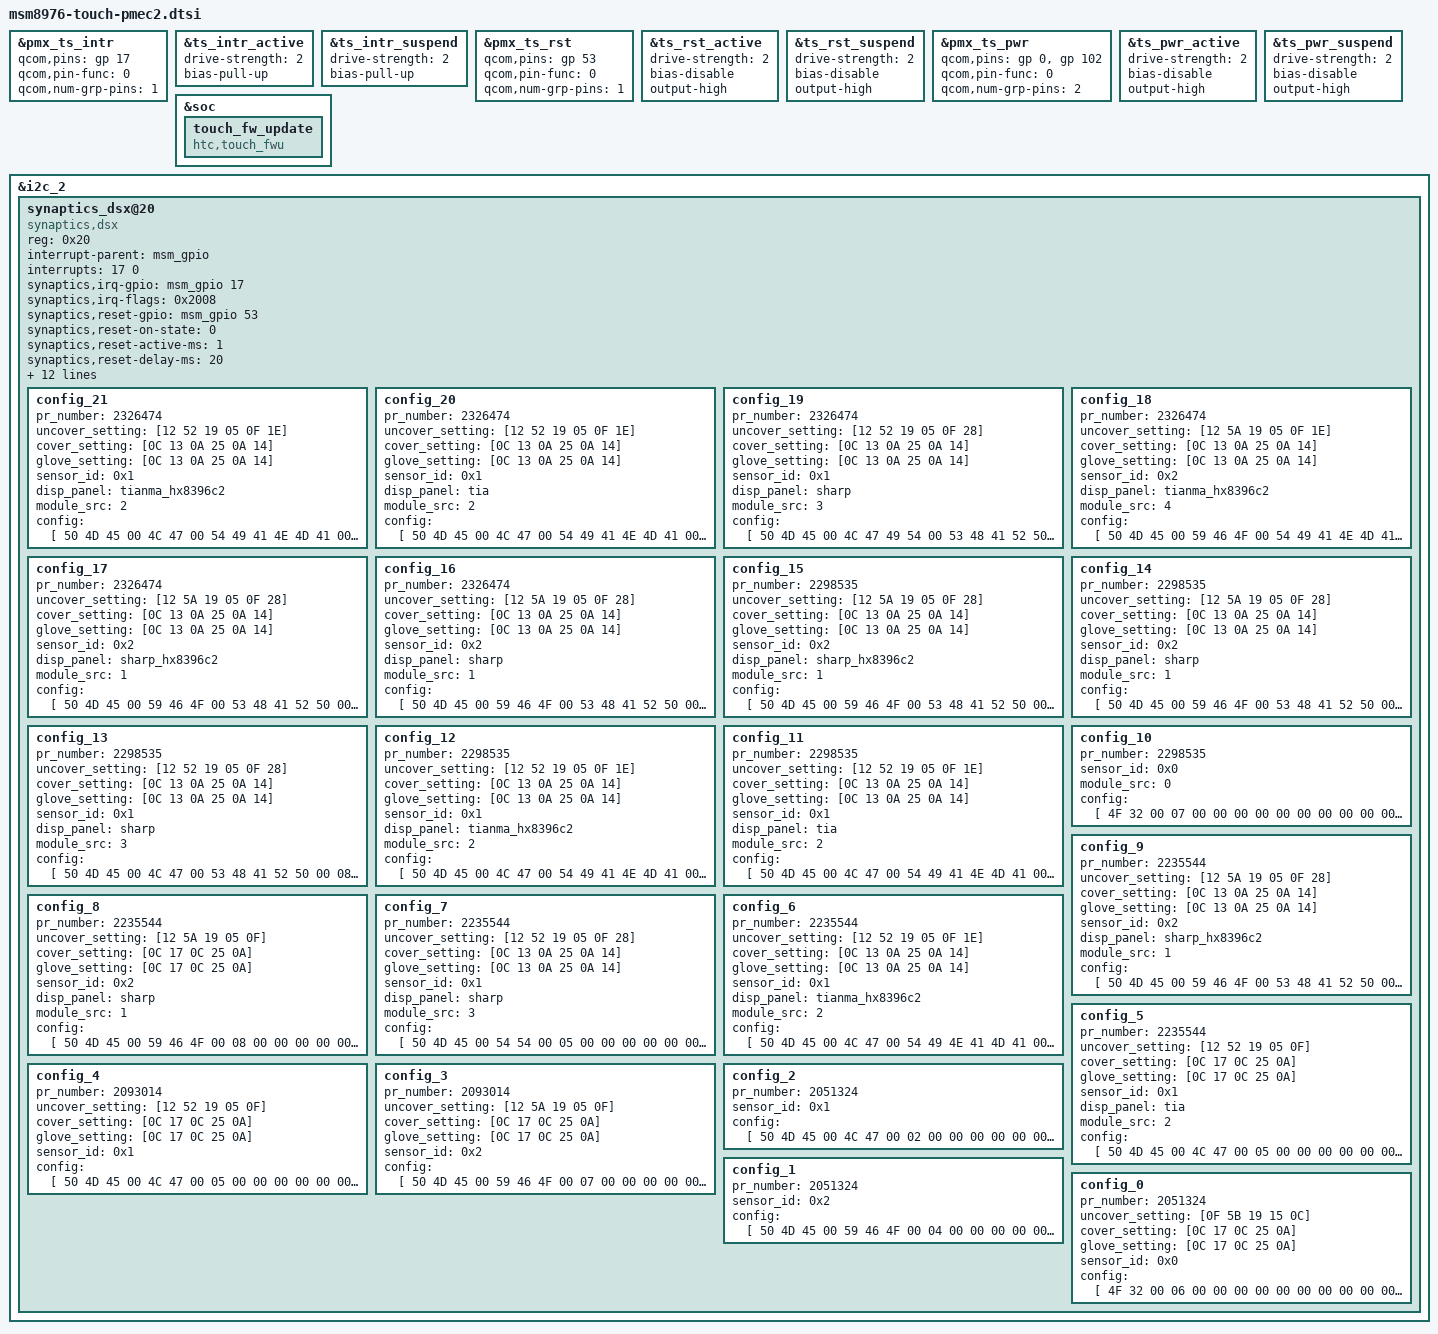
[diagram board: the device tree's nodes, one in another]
&pmx_ts_intr {
	qcom,pins = <&gp 17>;
	qcom,pin-func = <0>;
	qcom,num-grp-pins = <1>;
};

&ts_intr_active {
	drive-strength = <2>;
	bias-pull-up;
};

&ts_intr_suspend {
	drive-strength = <2>;
	bias-pull-up;
};

&pmx_ts_rst {
	qcom,pins = <&gp 53>;
	qcom,pin-func = <0>;
	qcom,num-grp-pins = <1>;
};

&ts_rst_active {
	drive-strength = <2>;
	bias-disable; /* No PULL */
	output-high;
};

&ts_rst_suspend {
	drive-strength = <2>;
	bias-disable; /* No PULL */
	output-high;
};

&pmx_ts_pwr {
	qcom,pins = <&gp 0>, <&gp 102>;
	qcom,pin-func = <0>;
	qcom,num-grp-pins = <2>;
};

&ts_pwr_active {
	drive-strength = <2>;
	bias-disable; /* No PULL */
	output-high;
};

&ts_pwr_suspend {
	drive-strength = <2>;
	bias-disable; /* No PULL */
	output-high;
};

&soc {
	touch_fw_update {
		compatible = "htc,touch_fwu";
	};
};

&i2c_2 {
	synaptics_dsx@20 {
		compatible = "synaptics,dsx";
		reg = <0x20>;
		interrupt-parent = <&msm_gpio>;
		interrupts = <17 0>;
		synaptics,irq-gpio = <&msm_gpio 17 0x00>;
		synaptics,irq-flags = <0x2008>;
		synaptics,reset-gpio = <&msm_gpio 53 0x00>;
		synaptics,reset-on-state = <0>;
		synaptics,reset-active-ms = <1>;
		synaptics,reset-delay-ms = <20>;
		synaptics,switch-gpio = <&msm_gpio 49 0x00>;
		synaptics,update-feature = <2>;
		synaptics,support-glove = <1>;
		synaptics,support-cover = <1>;
		synaptics,hall-block-time = <1000>;
		synaptics,setting-group=<1>;
		synaptics,display-coords = <0 1440 0 2560>;
		synaptics,tw-pin-mask = <0x3>;
		pinctrl-names = "pmx_ts_active", "pmx_ts_suspend";
		pinctrl-0 = <&ts_intr_active &ts_rst_active &ts_pwr_active>;
		pinctrl-1 = <&ts_intr_suspend &ts_rst_suspend &ts_pwr_suspend>;

		config_21 { /* LGIT + Tianma cut 2.0 */
			pr_number     = <2326474>;
			uncover_setting = [12 52 19 05 0F 1E];
			cover_setting = [0C 13 0A 25 0A 14];
			glove_setting = [0C 13 0A 25 0A 14];
			sensor_id = <0x1>;
			disp_panel = "tianma_hx8396c2";
			module_src = <2>;
			config = [
				50 4D 45 00 4C 47 00 54
				49 41 4E 4D 41 00 11 00
				00 00 00 00 00 00 00 00
				00 00 00 00 00 00 00 00
				00 4F 01 1E 05 51 0E 9F
				05 FF 09 7D 3D 79 3D 00
				00 00 00 11 1E 1E 05 C2
				04 F8 00 2D 19 01 15 02
				F0 D2 F0 D2 6D 0D 05 46
				00 00 0F 12 4B 0F 0A 78
				00 01 01 07 04 04 32 28
				08 C8 26 26 80 80 00 00
				FF 01 64 00 05 0F 00 FF
				05 01 28 FF C0 53 5B 80
				52 19 00 40 40 32 50 00
				00 00 00 4C 04 6C 07 3C
				32 00 00 00 00 4C 04 6C
				07 1E 05 1E 04 0A 04 0A
				00 0A 04 04 00 0A 78 02
				00 7D 00 02 00 C8 00 00
				00 96 00 00 00 00 01 05
				0A 00 00 00 78 00 96 00
				32 00 00 00 00 00 00 00
				00 00 0D 00 00 14 03 0C
				0F 0A 00 4B 00 00 FF FF
				FF FF FF FF FF FF FF FF
				FF FF FF FF FF FF FF FF
				FF FF FF FF FF FF FF FF
				FF FF FF FF FF FF FF 00
				01 00 00 32 00 14 00 14
				00 64 00 64 00 10 00 10
				00 7D 00 7D 00 40 66 58
				1B 28 00 FF FF FF FF FF
				FF FF FF FF FF FF FF FF
				FF FF FF 01 00 00 00 00
				00 00 00 00 00 00 00 00
				00 00 00 00 00 00 00 00
				00 00 FF 00 FF 14 55 09
				0E 3C 0A 0F 64 64 00 00
				00 00 00 00 00 00 00 00
				00 00 00 00 00 00 00 00
				FF FF FF FF FF FF FF FF
				FF FF FF FF FF FF FF FF
				FF FF FF FF FF FF FF FF
				FF FF FF FF FF FF FF FF
				FF FF FF FF FF FF FF FF
				FF FF FF FF FF FF FF FF
				FF FF FF FF FF FF FF FF
				FF FF FF FF FF FF FF FF
				00 00 6E 00 80 04 1B 00
				00 FF 2C 01 FF FF CC 03
				E8 03 00 C0 80 04 10 0A
				18 00 79 08 08 00 01 2C
				01 06 00 06 06 07 07 00
				2C 01 01 04 03 36 00 19
				00 00 00 02 00 01 28 04
				35 00 19 00 01 00 02 00
				01 29 84 34 00 18 00 02
				00 02 00 01 2A 83 33 00
				17 00 03 00 02 00 01 2B
				83 32 00 17 00 04 00 02
				00 01 2C 83 31 00 17 00
				05 00 02 00 01 2D 03 30
				00 16 00 06 00 05 00 02
				26 03 2F 00 16 00 07 00
				05 00 02 27 05 05 05 05
				05 05 05 05 05 05 05 05
				05 05 05 05 05 00 00 00
				00 00 00 00 00 00 00 00
				00 00 00 00 00 00 1B 00
				06 00 0A 00 0A 32 00 01
				1B 01 06 46 46 50 00 50
				00 00 8C 1E 03 0C 0C 14
				28 04 00 00 00 00 00 00
				00 00 00 00 18 00 80 07
				01 07 07 1D 1D 00 00 07
				07 01 07 07 1D 1D 00 00
				07 04 04 39 00 07 03 00
				36 22 00 05 03 00 25 01
				00 00 04 0C EE EE 00 0C
				EE EE AA 01 28 0C 11 11
				00 0C 66 66 AA 00 00 00
				FF FF FF FF FF FF FF FF
				51 51 51 51 CD 0D 04 83
				10 10 10 10 61 24 64 01
				1C 19 1E 1F 17 16 1A 18
				15 14 13 11 12 04 05 03
				06 FF FF FF FF FF FF FF
				FF FF FF FF FF FF FF FF
				FF FF 30 2E 2F 28 27 2D
				29 2A 2C 2B 26 23 24 25
				22 39 35 36 3A 3B 3E 3F
				31 3C 38 3D 37 00 32 01
				FF FF FF FF 00 10 00 10
				00 10 00 10 80 80 80 80
				80 80 80 80 80 80 80 80
				80 80 80 80 80 80 80 80
				80 80 80 80 80 80 80 80
				80 80 80 80 80 80 A6 9A
				8D 86 80 80 80 80 80 80
				80 80 80 80 80 80 80 80
				80 80 80 80 80 80 80 80
				80 80 80 80 80 80 80 80
				CD 14 CD 14 00 10 00 10
				00 00 1D FF FF FF FF FF
				FF FF 00 00 0F 00 44 44
				78
			];
		};

		config_20 { /* LGIT + Tianma */
			pr_number     = <2326474>;
			uncover_setting = [12 52 19 05 0F 1E];
			cover_setting = [0C 13 0A 25 0A 14];
			glove_setting = [0C 13 0A 25 0A 14];
			sensor_id = <0x1>;
			disp_panel = "tia";
			module_src = <2>;
			config = [
				50 4D 45 00 4C 47 00 54
				49 41 4E 4D 41 00 10 10
				00 00 00 00 00 00 00 00
				00 00 00 00 00 00 00 00
				00 4F 01 1E 05 51 0E 9F
				05 FF 09 7D 3D 79 3D 00
				00 00 00 11 1E 1E 05 C2
				04 F8 00 2D 19 01 15 02
				F0 D2 F0 D2 6D 0D 05 46
				00 00 0F 12 5F 0F 0A 78
				00 01 01 07 04 04 32 28
				08 C8 26 26 80 80 00 00
				FF 01 64 00 05 0F 00 FF
				05 01 28 FF C0 53 5B 80
				52 19 00 40 40 32 50 00
				00 00 00 4C 04 6C 07 3C
				32 00 00 00 00 4C 04 6C
				07 1E 05 1E 04 0A 04 0A
				00 0A 04 04 00 0A 78 02
				00 7D 00 02 00 C8 00 00
				00 96 00 00 00 00 01 05
				0A 00 00 00 78 00 96 00
				32 00 00 00 00 00 00 00
				00 00 0D 00 00 14 03 0C
				0F 0A 00 4B 00 00 FF FF
				FF FF FF FF FF FF FF FF
				FF FF FF FF FF FF FF FF
				FF FF FF FF FF FF FF FF
				FF FF FF FF FF FF FF 00
				01 00 00 32 00 14 00 14
				00 64 00 64 00 10 00 10
				00 7D 00 7D 00 40 66 58
				1B 28 00 FF FF FF FF FF
				FF FF FF FF FF FF FF FF
				FF FF FF 01 00 00 00 00
				00 00 00 00 00 00 00 00
				00 00 00 00 00 00 00 00
				00 00 FF 00 FF 14 55 09
				0E 3C 0A 0F 64 64 00 00
				00 00 00 00 00 00 00 00
				00 00 00 00 00 00 00 00
				FF FF FF FF FF FF FF FF
				FF FF FF FF FF FF FF FF
				FF FF FF FF FF FF FF FF
				FF FF FF FF FF FF FF FF
				FF FF FF FF FF FF FF FF
				FF FF FF FF FF FF FF FF
				FF FF FF FF FF FF FF FF
				FF FF FF FF FF FF FF FF
				00 00 6E 00 80 04 1B 00
				00 FF 2C 01 FF FF CC 03
				E8 03 00 C0 80 04 10 0A
				18 00 79 08 08 00 01 2C
				01 06 00 06 06 07 07 00
				2C 01 01 04 03 36 00 19
				00 00 00 02 00 01 28 04
				35 00 19 00 01 00 02 00
				01 29 84 34 00 18 00 02
				00 02 00 01 2A 83 33 00
				17 00 03 00 02 00 01 2B
				83 32 00 17 00 04 00 02
				00 01 2C 83 31 00 17 00
				05 00 02 00 01 2D 03 30
				00 16 00 06 00 05 00 02
				26 03 2F 00 16 00 07 00
				05 00 02 27 05 05 05 05
				05 05 05 05 05 05 05 05
				05 05 05 05 05 00 00 00
				00 00 00 00 00 00 00 00
				00 00 00 00 00 00 1B 00
				06 00 0A 00 0A 32 00 01
				1B 01 06 46 46 50 00 50
				00 00 8C 1E 03 0C 0C 14
				28 04 00 00 00 00 00 00
				00 00 00 00 18 00 80 07
				01 07 07 1D 1D 00 00 07
				07 01 07 07 1D 1D 00 00
				07 04 04 39 00 07 03 00
				36 22 00 05 03 00 25 01
				00 00 04 0C EE EE 00 0C
				EE EE AA 01 28 0C 11 11
				00 0C 66 66 AA 00 00 00
				FF FF FF FF FF FF FF FF
				51 51 51 51 CD 0D 04 83
				10 10 10 10 61 24 64 01
				1C 19 1E 1F 17 16 1A 18
				15 14 13 11 12 04 05 03
				06 FF FF FF FF FF FF FF
				FF FF FF FF FF FF FF FF
				FF FF 30 2E 2F 28 27 2D
				29 2A 2C 2B 26 23 24 25
				22 39 35 36 3A 3B 3E 3F
				31 3C 38 3D 37 00 32 01
				FF FF FF FF 00 10 00 10
				00 10 00 10 80 80 80 80
				80 80 80 80 80 80 80 80
				80 80 80 80 80 80 80 80
				80 80 80 80 80 80 80 80
				80 80 80 80 80 80 A6 9A
				8D 86 80 80 80 80 80 80
				80 80 80 80 80 80 80 80
				80 80 80 80 80 80 80 80
				80 80 80 80 80 80 80 80
				CD 14 CD 14 00 10 00 10
				00 00 1D FF FF FF FF FF
				FF FF 00 00 0F 00 44 44
				78
			];
		};

		config_19 { /* LGIT + Sharp (cut 2.0 only) */
			pr_number     = <2326474>;
			uncover_setting = [12 52 19 05 0F 28];
			cover_setting = [0C 13 0A 25 0A 14];
			glove_setting = [0C 13 0A 25 0A 14];
			sensor_id = <0x1>;
			disp_panel = "sharp";
			module_src = <3>;
			config = [
				50 4D 45 00 4C 47 49 54
				00 53 48 41 52 50 10 00
				00 00 00 00 00 00 00 00
				00 00 00 00 00 00 00 00
				00 4F 01 28 05 51 0E 9F
				05 FF 09 7D 3D 79 3D 00
				00 00 00 11 1E 1E 05 C2
				04 F8 00 2D 19 01 15 02
				F0 D2 F0 D2 6D 0D 05 46
				00 00 0F 12 5F 0F 0A 78
				00 01 01 07 04 04 32 28
				08 7D 26 26 80 80 00 00
				FF 01 64 00 05 0F 00 FF
				05 01 28 FF C0 53 5B 80
				52 19 00 40 40 32 50 00
				00 00 00 4C 04 6C 07 3C
				32 00 00 00 00 4C 04 6C
				07 1E 05 1E 04 0A 04 0A
				00 0A 04 04 00 0A 78 02
				00 7D 00 02 00 C8 00 00
				00 96 00 00 00 00 01 05
				0A 00 00 00 78 00 96 00
				32 00 00 00 00 00 00 00
				00 00 0D 00 00 14 03 0C
				0F 0A 00 4B 00 00 FF FF
				FF FF FF FF FF FF FF FF
				FF FF FF FF FF FF FF FF
				FF FF FF FF FF FF FF FF
				FF FF FF FF FF FF FF 00
				01 00 00 32 00 14 00 14
				00 64 00 64 00 10 00 10
				00 7D 00 7D 00 40 66 58
				1B 28 00 FF FF FF FF FF
				FF FF FF FF FF FF FF FF
				FF FF FF 01 00 00 00 00
				00 00 00 00 00 00 00 00
				00 00 00 00 00 00 00 00
				00 00 FF 00 FF 14 55 09
				0E 3C 0A 0F 64 64 00 00
				00 00 00 00 00 00 00 00
				00 00 00 00 00 00 00 00
				FF FF FF FF FF FF FF FF
				FF FF FF FF FF FF FF FF
				FF FF FF FF FF FF FF FF
				FF FF FF FF FF FF FF FF
				FF FF FF FF FF FF FF FF
				FF FF FF FF FF FF FF FF
				FF FF FF FF FF FF FF FF
				FF FF FF FF FF FF FF FF
				00 00 6E 00 80 04 1B 00
				00 FF 20 03 FF FF CC 03
				DC 05 00 C0 80 04 10 0A
				18 00 79 08 06 00 01 20
				03 06 00 06 06 07 07 00
				2C 01 01 04 03 36 00 19
				00 00 00 02 00 01 28 04
				35 00 19 00 01 00 02 00
				01 29 84 34 00 18 00 02
				00 02 00 01 2A 83 33 00
				17 00 03 00 02 00 01 2B
				83 32 00 17 00 04 00 02
				00 01 2C 83 31 00 17 00
				05 00 02 00 01 2D 03 30
				00 16 00 06 00 05 00 02
				26 03 2F 00 16 00 07 00
				05 00 02 27 05 05 05 05
				05 05 05 05 05 05 05 05
				05 05 05 05 05 00 00 00
				00 00 00 00 00 00 00 00
				00 00 00 00 00 00 1B 00
				06 00 0A 00 0A 32 00 01
				1B 01 06 46 46 50 00 50
				00 00 8C 1E 03 0C 0C 14
				28 04 00 00 00 00 00 00
				00 00 00 00 18 00 80 07
				01 07 07 1D 1D 00 00 07
				07 01 07 07 1D 1D 00 00
				07 04 04 2D 00 07 03 00
				36 22 00 05 03 00 25 01
				00 00 04 0C EE EE 00 0C
				EE EE AA 01 3C 0C 11 11
				00 0C 66 66 AA 00 00 00
				FF FF FF FF FF FF FF FF
				51 51 51 51 CD 0D 04 83
				10 10 10 10 61 24 64 01
				1C 19 1E 1F 17 16 1A 18
				15 14 13 11 12 04 05 03
				06 FF FF FF FF FF FF FF
				FF FF FF FF FF FF FF FF
				FF FF 30 2E 2F 28 27 2D
				29 2A 2C 2B 26 23 24 25
				22 39 35 36 3A 3B 3E 3F
				31 3C 38 3D 37 00 32 01
				FF FF FF FF 00 10 00 10
				00 10 00 10 80 80 80 80
				80 80 80 80 80 80 80 80
				80 80 80 80 80 80 80 80
				80 80 80 80 80 80 80 80
				80 80 80 80 80 80 A6 9A
				8D 86 80 80 80 80 80 80
				80 80 80 80 80 80 80 80
				80 80 80 80 80 80 80 80
				80 80 80 80 80 80 80 80
				CD 14 CD 14 00 10 00 10
				00 00 1D FF FF FF FF FF
				FF FF 00 00 0F 00 44 44
				78
			];
		};

		config_18 { /* YFO_R2 + Tianma (cut 2.0 only) */
			pr_number     = <2326474>;
			uncover_setting = [12 5A 19 05 0F 1E];
			cover_setting = [0C 13 0A 25 0A 14];
			glove_setting = [0C 13 0A 25 0A 14];
			sensor_id = <0x2>;
			disp_panel = "tianma_hx8396c2";
			module_src = <4>;
			config = [
				50 4D 45 00 59 46 4F 00
				54 49 41 4E 4D 41 00 02
				00 00 00 00 00 00 00 00
				00 00 00 00 00 00 00 00
				00 4F 01 1E 05 51 0E 9F
				05 FF 09 7D 3D 79 3D 00
				00 00 00 11 1E 1E 05 C2
				04 F8 00 2D 19 01 15 02
				F0 D2 F0 D2 6D 0D 05 46
				00 00 0F 12 4B 0F 0A 78
				00 01 01 07 04 04 32 28
				08 C8 26 26 80 80 00 00
				FF 01 64 00 05 0F 00 FF
				05 01 28 FF C0 53 5B 80
				5A 19 00 40 40 32 50 00
				00 00 00 4C 04 6C 07 3C
				32 00 00 00 00 4C 04 6C
				07 1E 05 1E 04 0A 04 0A
				00 0A 04 04 00 0A 78 02
				00 7D 00 02 00 C8 00 00
				00 96 00 00 00 00 01 05
				0A 00 00 00 78 00 96 00
				32 00 00 00 00 00 00 00
				00 00 0D 00 00 14 03 0C
				0F 0A 00 4B 00 00 FF FF
				FF FF FF FF FF FF FF FF
				FF FF FF FF FF FF FF FF
				FF FF FF FF FF FF FF FF
				FF FF FF FF FF FF FF 00
				01 00 00 32 00 14 00 14
				00 64 00 64 00 10 00 10
				00 7D 00 7D 00 40 66 58
				1B 28 00 FF FF FF FF FF
				FF FF FF FF FF FF FF FF
				FF FF FF 01 00 00 00 00
				00 00 00 00 00 00 00 00
				00 00 00 00 00 00 00 00
				00 00 FF 00 FF 14 55 09
				0E 3C 0A 0F 64 64 00 00
				00 00 00 00 00 00 00 00
				00 00 00 00 00 00 00 00
				FF FF FF FF FF FF FF FF
				FF FF FF FF FF FF FF FF
				FF FF FF FF FF FF FF FF
				FF FF FF FF FF FF FF FF
				FF FF FF FF FF FF FF FF
				FF FF FF FF FF FF FF FF
				FF FF FF FF FF FF FF FF
				FF FF FF FF FF FF FF FF
				00 00 6E 00 80 04 1B 00
				00 FF 2C 01 FF FF CC 03
				E8 03 00 C0 80 04 10 0A
				18 00 79 08 08 00 01 2C
				01 06 00 06 06 07 07 00
				2C 01 01 04 03 36 00 19
				00 00 00 02 00 01 28 04
				35 00 19 00 01 00 02 00
				01 29 84 34 00 18 00 02
				00 02 00 01 2A 83 33 00
				17 00 03 00 02 00 01 2B
				83 32 00 17 00 04 00 02
				00 01 2C 83 31 00 17 00
				05 00 02 00 01 2D 03 30
				00 16 00 06 00 05 00 02
				26 03 2F 00 16 00 07 00
				05 00 02 27 05 05 05 05
				05 05 05 05 05 05 05 05
				05 05 05 05 05 00 00 00
				00 00 00 00 00 00 00 00
				00 00 00 00 00 00 1B 00
				06 00 0A 00 0A 32 00 01
				1B 01 06 46 46 50 00 50
				00 00 8C 1E 03 0C 0C 14
				28 04 00 00 00 00 00 00
				00 00 00 00 18 00 80 07
				01 07 07 1D 1D 00 00 07
				07 01 07 07 1D 1D 00 00
				07 04 04 39 00 07 03 00
				36 22 00 05 03 00 25 01
				00 00 04 0C EE EE 00 0C
				EE EE AA 01 28 0C 11 11
				00 0C 66 66 AA 00 00 00
				FF FF FF FF FF FF FF FF
				51 51 51 51 CD 0D 04 83
				10 10 10 10 61 24 64 01
				1C 19 1E 1F 17 16 1A 18
				15 14 13 11 12 04 05 03
				06 FF FF FF FF FF FF FF
				FF FF FF FF FF FF FF FF
				FF FF 30 2E 2F 28 27 2D
				29 2A 2C 2B 26 23 24 25
				22 39 35 3C 3A 3B 3E 3F
				31 36 38 3D 37 00 32 01
				FF FF FF FF 00 10 00 10
				00 10 00 10 80 80 80 80
				80 80 80 80 80 80 80 80
				80 80 80 80 80 80 80 80
				80 80 80 80 80 80 80 80
				80 80 80 80 80 80 A6 9A
				8D 86 80 80 80 80 80 80
				80 80 80 80 80 80 80 80
				80 80 80 80 80 80 80 80
				80 80 80 80 80 80 80 80
				CD 14 CD 14 00 10 00 10
				00 00 1D FF FF FF FF FF
				FF FF 00 00 0F 00 44 44
				78
			];
		};

		config_17 { /* YFO R2 + Sharp cut 2.0 */
			pr_number     = <2326474>;
			uncover_setting = [12 5A 19 05 0F 28];
			cover_setting = [0C 13 0A 25 0A 14];
			glove_setting = [0C 13 0A 25 0A 14];
			sensor_id = <0x2>;
			disp_panel = "sharp_hx8396c2";
			module_src = <1>;
			config = [
				50 4D 45 00 59 46 4F 00
				53 48 41 52 50 00 11 00
				00 00 00 00 00 00 00 00
				00 00 00 00 00 00 00 00
				00 4F 01 28 05 51 0E 9F
				05 FF 09 7D 3D 79 3D 00
				00 00 00 11 1E 1E 05 6B
				08 60 01 2D 17 02 14 02
				F0 D2 F0 D2 6D 0D 05 46
				00 00 0F 12 4B 0F 0A 78
				00 01 01 07 04 04 32 28
				08 7D 26 26 80 80 00 00
				FF 01 64 00 05 0F 00 FF
				05 01 28 FF C0 53 5B 80
				5A 19 00 40 40 32 50 00
				00 00 00 4C 04 6C 07 3C
				32 00 00 00 00 4C 04 6C
				07 1E 05 1E 04 0A 04 0A
				00 0A 04 04 00 0A 78 02
				00 7D 00 02 00 C8 00 00
				00 96 00 00 00 00 01 05
				0A 00 00 00 78 00 96 00
				32 00 00 00 00 00 00 00
				00 00 0D 00 00 14 03 0C
				0F 0A 00 4B 00 00 FF FF
				FF FF FF FF FF FF FF FF
				FF FF FF FF FF FF FF FF
				FF FF FF FF FF FF FF FF
				FF FF FF FF FF FF FF 00
				01 00 00 32 00 14 00 14
				00 64 00 64 00 10 00 10
				00 7D 00 7D 00 40 66 58
				1B 28 00 FF FF FF FF FF
				FF FF FF FF FF FF FF FF
				FF FF FF 01 00 00 00 00
				00 00 00 00 00 00 00 00
				00 00 00 00 00 00 00 00
				00 00 FF 00 FF 14 55 09
				0E 3C 0A 0F 64 64 00 00
				00 00 00 00 00 00 00 00
				00 00 00 00 00 00 00 00
				FF FF FF FF FF FF FF FF
				FF FF FF FF FF FF FF FF
				FF FF FF FF FF FF FF FF
				FF FF FF FF FF FF FF FF
				FF FF FF FF FF FF FF FF
				FF FF FF FF FF FF FF FF
				FF FF FF FF FF FF FF FF
				FF FF FF FF FF FF FF FF
				00 00 6E 00 80 04 1B 00
				00 FF 20 03 FF FF CC 03
				DC 05 00 C0 80 04 10 0A
				18 00 79 08 06 00 01 20
				03 06 00 03 03 07 07 03
				2C 01 01 04 03 36 00 19
				00 00 00 02 00 01 28 04
				35 00 19 00 01 00 02 00
				01 29 84 34 00 18 00 02
				00 02 00 01 2A 83 33 00
				17 00 03 00 02 00 01 2B
				83 32 00 17 00 04 00 02
				00 01 2C 83 31 00 17 00
				05 00 02 00 01 2D 03 30
				00 16 00 06 00 05 00 02
				26 03 2F 00 16 00 07 00
				05 00 02 27 06 06 06 06
				06 06 06 06 06 06 06 05
				05 05 05 06 05 00 00 00
				00 00 00 00 00 00 00 00
				00 00 00 00 00 00 1B 00
				06 00 0A 00 0A 32 00 01
				1B 01 06 46 46 50 00 50
				00 00 8C 1E 03 0C 0C 14
				28 04 00 00 00 00 00 00
				00 00 00 00 18 00 80 07
				01 07 07 1D 1D 00 00 07
				07 01 07 07 1D 1D 00 00
				07 04 04 2D 00 07 03 00
				36 22 00 05 03 00 25 01
				00 00 04 0C EE EE 00 0C
				EE EE AA 01 3C 0C 11 11
				00 0C 66 66 AA 00 00 00
				FF FF FF FF FF FF FF FF
				51 51 51 51 CD 0D 04 83
				10 10 10 10 61 24 64 01
				1C 19 1E 1F 17 16 1A 18
				15 14 13 11 12 04 05 03
				06 FF FF FF FF FF FF FF
				FF FF FF FF FF FF FF FF
				FF FF 30 2E 2F 28 27 2D
				29 2A 2C 2B 26 23 24 25
				22 39 35 3C 3A 3B 3E 3F
				31 36 38 3D 37 00 32 01
				FF FF FF FF 00 10 00 10
				00 10 00 10 80 80 80 80
				80 80 80 80 80 80 80 80
				80 80 80 80 80 80 80 80
				80 80 80 80 80 80 80 80
				80 80 80 80 80 80 A6 9A
				8D 86 80 80 80 80 80 80
				80 80 80 80 80 80 80 80
				80 80 80 80 80 80 80 80
				80 80 80 80 80 80 80 80
				CD 14 CD 14 00 10 00 10
				00 00 1D FF FF FF FF FF
				FF FF 00 00 0F 00 44 44
				78
			];
		};

		config_16 { /* YFO R2 + Sharp */
			pr_number     = <2326474>;
			uncover_setting = [12 5A 19 05 0F 28];
			cover_setting = [0C 13 0A 25 0A 14];
			glove_setting = [0C 13 0A 25 0A 14];
			sensor_id = <0x2>;
			disp_panel = "sharp";
			module_src = <1>;
			config = [
				50 4D 45 00 59 46 4F 00
				53 48 41 52 50 00 10 10
				00 00 00 00 00 00 00 00
				00 00 00 00 00 00 00 00
				00 4F 01 28 05 51 0E 9F
				05 FF 09 7D 3D 79 3D 00
				00 00 00 11 1E 1E 05 6B
				08 60 01 2D 17 02 14 02
				F0 D2 F0 D2 6D 0D 05 46
				00 00 0F 12 5F 0F 0A 78
				00 01 01 07 04 04 32 28
				08 7D 26 26 80 80 00 00
				FF 01 64 00 05 0F 00 FF
				05 01 28 FF C0 53 5B 80
				5A 19 00 40 40 32 50 00
				00 00 00 4C 04 6C 07 3C
				32 00 00 00 00 4C 04 6C
				07 1E 05 1E 04 0A 04 0A
				00 0A 04 04 00 0A 78 02
				00 7D 00 02 00 C8 00 00
				00 96 00 00 00 00 01 05
				0A 00 00 00 78 00 96 00
				32 00 00 00 00 00 00 00
				00 00 0D 00 00 14 03 0C
				0F 0A 00 4B 00 00 FF FF
				FF FF FF FF FF FF FF FF
				FF FF FF FF FF FF FF FF
				FF FF FF FF FF FF FF FF
				FF FF FF FF FF FF FF 00
				01 00 00 32 00 14 00 14
				00 64 00 64 00 10 00 10
				00 7D 00 7D 00 40 66 58
				1B 28 00 FF FF FF FF FF
				FF FF FF FF FF FF FF FF
				FF FF FF 01 00 00 00 00
				00 00 00 00 00 00 00 00
				00 00 00 00 00 00 00 00
				00 00 FF 00 FF 14 55 09
				0E 3C 0A 0F 64 64 00 00
				00 00 00 00 00 00 00 00
				00 00 00 00 00 00 00 00
				FF FF FF FF FF FF FF FF
				FF FF FF FF FF FF FF FF
				FF FF FF FF FF FF FF FF
				FF FF FF FF FF FF FF FF
				FF FF FF FF FF FF FF FF
				FF FF FF FF FF FF FF FF
				FF FF FF FF FF FF FF FF
				FF FF FF FF FF FF FF FF
				00 00 6E 00 80 04 1B 00
				00 FF 20 03 FF FF CC 03
				DC 05 00 C0 80 04 10 0A
				18 00 79 08 06 00 01 20
				03 06 00 03 03 07 07 03
				2C 01 01 04 03 36 00 19
				00 00 00 02 00 01 28 04
				35 00 19 00 01 00 02 00
				01 29 84 34 00 18 00 02
				00 02 00 01 2A 83 33 00
				17 00 03 00 02 00 01 2B
				83 32 00 17 00 04 00 02
				00 01 2C 83 31 00 17 00
				05 00 02 00 01 2D 03 30
				00 16 00 06 00 05 00 02
				26 03 2F 00 16 00 07 00
				05 00 02 27 06 06 06 06
				06 06 06 06 06 06 06 05
				05 05 05 06 05 00 00 00
				00 00 00 00 00 00 00 00
				00 00 00 00 00 00 1B 00
				06 00 0A 00 0A 32 00 01
				1B 01 06 46 46 50 00 50
				00 00 8C 1E 03 0C 0C 14
				28 04 00 00 00 00 00 00
				00 00 00 00 18 00 80 07
				01 07 07 1D 1D 00 00 07
				07 01 07 07 1D 1D 00 00
				07 04 04 2D 00 07 03 00
				36 22 00 05 03 00 25 01
				00 00 04 0C EE EE 00 0C
				EE EE AA 01 3C 0C 11 11
				00 0C 66 66 AA 00 00 00
				FF FF FF FF FF FF FF FF
				51 51 51 51 CD 0D 04 83
				10 10 10 10 61 24 64 01
				1C 19 1E 1F 17 16 1A 18
				15 14 13 11 12 04 05 03
				06 FF FF FF FF FF FF FF
				FF FF FF FF FF FF FF FF
				FF FF 30 2E 2F 28 27 2D
				29 2A 2C 2B 26 23 24 25
				22 39 35 3C 3A 3B 3E 3F
				31 36 38 3D 37 00 32 01
				FF FF FF FF 00 10 00 10
				00 10 00 10 80 80 80 80
				80 80 80 80 80 80 80 80
				80 80 80 80 80 80 80 80
				80 80 80 80 80 80 80 80
				80 80 80 80 80 80 A6 9A
				8D 86 80 80 80 80 80 80
				80 80 80 80 80 80 80 80
				80 80 80 80 80 80 80 80
				80 80 80 80 80 80 80 80
				CD 14 CD 14 00 10 00 10
				00 00 1D FF FF FF FF FF
				FF FF 00 00 0F 00 44 44
				78
			];
		};

		config_15 { /* YFO R2 + Sharp cut 2.0 */
			pr_number     = <2298535>;
			uncover_setting = [12 5A 19 05 0F 28];
			cover_setting = [0C 13 0A 25 0A 14];
			glove_setting = [0C 13 0A 25 0A 14];
			sensor_id = <0x2>;
			disp_panel = "sharp_hx8396c2";
			module_src = <1>;
			config = [
				50 4D 45 00 59 46 4F 00
				53 48 41 52 50 00 08 00
				00 00 00 00 00 00 00 00
				00 00 00 00 00 00 00 00
				00 4F 01 28 05 51 0E 9F
				05 FF 09 7D 3D 79 3D 00
				00 00 00 11 1E 1E 05 6B
				08 60 01 2D 17 02 14 02
				F0 D2 F0 D2 6D 0D 05 46
				00 00 0F 12 5F 0F 0A 78
				00 01 01 07 04 04 32 28
				08 7D 26 26 80 80 00 00
				FF 01 64 00 05 0A 00 FF
				05 01 28 FF C0 53 5B 80
				5A 19 00 40 40 32 50 00
				00 00 00 4C 04 6C 07 3C
				32 00 00 00 00 4C 04 6C
				07 1E 05 1E 04 0A 04 0A
				00 0A 04 04 00 0A 78 02
				00 7D 00 02 00 C8 00 00
				00 96 00 00 00 00 01 05
				0A 00 00 00 78 00 96 00
				32 00 00 00 00 00 00 00
				00 00 0D 00 00 14 03 0C
				0F 0A 00 4B 00 00 FF FF
				FF FF FF FF FF FF FF FF
				FF FF FF FF FF FF FF FF
				FF FF FF FF FF FF FF FF
				FF FF FF FF FF FF FF 00
				01 00 00 32 00 14 00 14
				00 64 00 64 00 10 00 10
				00 7D 00 7D 00 40 66 58
				1B 28 00 FF FF FF FF FF
				FF FF FF FF FF FF FF FF
				FF FF FF 01 00 00 00 00
				00 00 00 00 00 00 00 00
				00 00 00 00 00 00 00 00
				00 00 FF 00 FF 14 55 09
				0E 3C 0A 0F 64 64 00 00
				00 00 00 00 00 00 00 00
				00 00 00 00 00 00 00 00
				FF FF FF FF FF FF FF FF
				FF FF FF FF FF FF FF FF
				FF FF FF FF FF FF FF FF
				FF FF FF FF FF FF FF FF
				FF FF FF FF FF FF FF FF
				FF FF FF FF FF FF FF FF
				FF FF FF FF FF FF FF FF
				FF FF FF FF FF FF FF FF
				00 00 6E 00 80 04 1B 00
				00 FF 2C 01 FF FF CC 03
				E8 03 00 C0 80 04 10 0A
				18 00 79 08 08 00 01 2C
				01 06 00 03 03 07 07 03
				2C 01 01 04 03 36 00 19
				00 00 00 02 00 01 28 04
				35 00 19 00 01 00 02 00
				01 29 84 34 00 18 00 02
				00 02 00 01 2A 83 33 00
				17 00 03 00 02 00 01 2B
				83 32 00 17 00 04 00 02
				00 01 2C 83 31 00 17 00
				05 00 02 00 01 2D 03 30
				00 16 00 06 00 05 00 02
				26 03 2F 00 16 00 07 00
				05 00 02 27 06 06 06 06
				06 06 06 06 06 06 06 05
				05 05 05 06 05 00 00 00
				00 00 00 00 00 00 00 00
				00 00 00 00 00 00 1B 00
				06 00 0A 00 0A 32 00 01
				1B 01 06 46 46 50 00 50
				00 00 8C 1E 03 0C 0C 14
				28 04 00 00 00 00 00 00
				00 00 00 00 18 00 80 07
				01 07 07 1D 1D 00 00 07
				07 01 07 07 1D 1D 00 00
				07 04 04 39 00 07 03 00
				36 22 00 05 03 00 25 01
				00 00 04 0C EE EE 00 0C
				EE EE AA 01 3C 0C 11 11
				00 0C 66 66 AA 00 00 00
				FF FF FF FF FF FF FF FF
				51 51 51 51 CD 0D 04 83
				10 10 10 10 61 24 64 01
				1C 19 1E 1F 17 16 1A 18
				15 14 13 11 12 04 05 03
				06 FF FF FF FF FF FF FF
				FF FF FF FF FF FF FF FF
				FF FF 30 2E 2F 28 27 2D
				29 2A 2C 2B 26 23 24 25
				22 39 35 3C 3A 3B 3E 3F
				31 36 38 3D 37 00 32 01
				FF FF FF FF 00 10 00 10
				00 10 00 10 80 80 80 80
				80 80 80 80 80 80 80 80
				80 80 80 80 80 80 80 80
				80 80 80 80 80 80 80 80
				80 80 80 80 80 80 A6 9A
				8D 86 80 80 80 80 80 80
				80 80 80 80 80 80 80 80
				80 80 80 80 80 80 80 80
				80 80 80 80 80 80 80 80
				CD 14 CD 14 00 10 00 10
				00 00 1D FF FF FF FF FF
				FF FF 00 00 0F 00 44 44
				78
			];
		};

		config_14 { /* YFO R2 + Sharp */
			pr_number     = <2298535>;
			uncover_setting = [12 5A 19 05 0F 28];
			cover_setting = [0C 13 0A 25 0A 14];
			glove_setting = [0C 13 0A 25 0A 14];
			sensor_id = <0x2>;
			disp_panel = "sharp";
			module_src = <1>;
			config = [
				50 4D 45 00 59 46 4F 00
				53 48 41 52 50 00 08 10
				00 00 00 00 00 00 00 00
				00 00 00 00 00 00 00 00
				00 4F 01 28 05 51 0E 9F
				05 FF 09 7D 3D 79 3D 00
				00 00 00 11 1E 1E 05 6B
				08 60 01 2D 17 02 14 02
				F0 D2 F0 D2 6D 0D 05 46
				00 00 0F 12 5F 0F 0A 78
				00 01 01 07 04 04 32 28
				08 7D 26 26 80 80 00 00
				FF 01 64 00 05 0A 00 FF
				05 01 28 FF C0 53 5B 80
				5A 19 00 40 40 32 50 00
				00 00 00 4C 04 6C 07 3C
				32 00 00 00 00 4C 04 6C
				07 1E 05 1E 04 0A 04 0A
				00 0A 04 04 00 0A 78 02
				00 7D 00 02 00 C8 00 00
				00 96 00 00 00 00 01 05
				0A 00 00 00 78 00 96 00
				32 00 00 00 00 00 00 00
				00 00 0D 00 00 14 03 0C
				0F 0A 00 4B 00 00 FF FF
				FF FF FF FF FF FF FF FF
				FF FF FF FF FF FF FF FF
				FF FF FF FF FF FF FF FF
				FF FF FF FF FF FF FF 00
				01 00 00 32 00 14 00 14
				00 64 00 64 00 10 00 10
				00 7D 00 7D 00 40 66 58
				1B 28 00 FF FF FF FF FF
				FF FF FF FF FF FF FF FF
				FF FF FF 01 00 00 00 00
				00 00 00 00 00 00 00 00
				00 00 00 00 00 00 00 00
				00 00 FF 00 FF 14 55 09
				0E 3C 0A 0F 64 64 00 00
				00 00 00 00 00 00 00 00
				00 00 00 00 00 00 00 00
				FF FF FF FF FF FF FF FF
				FF FF FF FF FF FF FF FF
				FF FF FF FF FF FF FF FF
				FF FF FF FF FF FF FF FF
				FF FF FF FF FF FF FF FF
				FF FF FF FF FF FF FF FF
				FF FF FF FF FF FF FF FF
				FF FF FF FF FF FF FF FF
				00 00 6E 00 80 04 1B 00
				00 FF 2C 01 FF FF CC 03
				E8 03 00 C0 80 04 10 0A
				18 00 79 08 08 00 01 2C
				01 06 00 03 03 07 07 03
				2C 01 01 04 03 36 00 19
				00 00 00 02 00 01 28 04
				35 00 19 00 01 00 02 00
				01 29 84 34 00 18 00 02
				00 02 00 01 2A 83 33 00
				17 00 03 00 02 00 01 2B
				83 32 00 17 00 04 00 02
				00 01 2C 83 31 00 17 00
				05 00 02 00 01 2D 03 30
				00 16 00 06 00 05 00 02
				26 03 2F 00 16 00 07 00
				05 00 02 27 06 06 06 06
				06 06 06 06 06 06 06 05
				05 05 05 06 05 00 00 00
				00 00 00 00 00 00 00 00
				00 00 00 00 00 00 1B 00
				06 00 0A 00 0A 32 00 01
				1B 01 06 46 46 50 00 50
				00 00 8C 1E 03 0C 0C 14
				28 04 00 00 00 00 00 00
				00 00 00 00 18 00 80 07
				01 07 07 1D 1D 00 00 07
				07 01 07 07 1D 1D 00 00
				07 04 04 39 00 07 03 00
				36 22 00 05 03 00 25 01
				00 00 04 0C EE EE 00 0C
				EE EE AA 01 3C 0C 11 11
				00 0C 66 66 AA 00 00 00
				FF FF FF FF FF FF FF FF
				51 51 51 51 CD 0D 04 83
				10 10 10 10 61 24 64 01
				1C 19 1E 1F 17 16 1A 18
				15 14 13 11 12 04 05 03
				06 FF FF FF FF FF FF FF
				FF FF FF FF FF FF FF FF
				FF FF 30 2E 2F 28 27 2D
				29 2A 2C 2B 26 23 24 25
				22 39 35 3C 3A 3B 3E 3F
				31 36 38 3D 37 00 32 01
				FF FF FF FF 00 10 00 10
				00 10 00 10 80 80 80 80
				80 80 80 80 80 80 80 80
				80 80 80 80 80 80 80 80
				80 80 80 80 80 80 80 80
				80 80 80 80 80 80 A6 9A
				8D 86 80 80 80 80 80 80
				80 80 80 80 80 80 80 80
				80 80 80 80 80 80 80 80
				80 80 80 80 80 80 80 80
				CD 14 CD 14 00 10 00 10
				00 00 1D FF FF FF FF FF
				FF FF 00 00 0F 00 44 44
				78
			];
		};

		config_13 { /* LGIT + Sharp (cut 2.0 only) */
			pr_number     = <2298535>;
			uncover_setting = [12 52 19 05 0F 28];
			cover_setting = [0C 13 0A 25 0A 14];
			glove_setting = [0C 13 0A 25 0A 14];
			sensor_id = <0x1>;
			disp_panel = "sharp";
			module_src = <3>;
			config = [
				50 4D 45 00 4C 47 00 53
				48 41 52 50 00 08 00 00
				00 00 00 00 00 00 00 00
				00 00 00 00 00 00 00 00
				00 4F 01 28 05 51 0E 9F
				05 FF 09 7D 3D 79 3D 00
				00 00 00 11 1E 1E 05 C2
				04 F8 00 2D 19 01 15 02
				F0 D2 F0 D2 6D 0D 05 46
				00 00 0F 12 5F 0F 0A 78
				00 01 01 07 04 04 32 28
				08 C8 26 26 80 80 00 00
				FF 01 64 00 05 0A 00 FF
				05 01 28 FF C0 53 5B 80
				52 19 00 40 40 32 50 00
				00 00 00 4C 04 6C 07 3C
				32 00 00 00 00 4C 04 6C
				07 1E 05 1E 04 0A 04 0A
				00 0A 04 04 00 0A 78 02
				00 7D 00 02 00 C8 00 00
				00 96 00 00 00 00 01 05
				0A 00 00 00 78 00 96 00
				32 00 00 00 00 00 00 00
				00 00 0D 00 00 14 03 0C
				0F 0A 00 4B 00 00 FF FF
				FF FF FF FF FF FF FF FF
				FF FF FF FF FF FF FF FF
				FF FF FF FF FF FF FF FF
				FF FF FF FF FF FF FF 00
				01 00 00 32 00 14 00 14
				00 64 00 64 00 10 00 10
				00 7D 00 7D 00 40 66 58
				1B 28 00 FF FF FF FF FF
				FF FF FF FF FF FF FF FF
				FF FF FF 01 00 00 00 00
				00 00 00 00 00 00 00 00
				00 00 00 00 00 00 00 00
				00 00 FF 00 FF 14 55 09
				0E 3C 0A 0F 64 64 00 00
				00 00 00 00 00 00 00 00
				00 00 00 00 00 00 00 00
				FF FF FF FF FF FF FF FF
				FF FF FF FF FF FF FF FF
				FF FF FF FF FF FF FF FF
				FF FF FF FF FF FF FF FF
				FF FF FF FF FF FF FF FF
				FF FF FF FF FF FF FF FF
				FF FF FF FF FF FF FF FF
				FF FF FF FF FF FF FF FF
				00 00 6E 00 80 04 1B 00
				00 FF 2C 01 FF FF CC 03
				E8 03 00 C0 80 04 10 0A
				18 00 79 08 08 00 01 2C
				01 06 00 06 06 07 07 00
				2C 01 01 04 03 36 00 19
				00 00 00 02 00 01 28 84
				35 00 19 00 01 00 02 00
				01 29 04 34 00 18 00 02
				00 02 00 01 2A 83 33 00
				17 00 03 00 02 00 01 2B
				83 32 00 17 00 04 00 02
				00 01 2C 03 31 00 17 00
				05 00 02 00 01 2D 83 30
				00 16 00 06 00 05 00 02
				26 03 2F 00 16 00 07 00
				05 00 02 27 05 05 05 05
				05 05 05 05 05 05 05 05
				05 05 05 05 05 00 00 00
				00 00 00 00 00 00 00 00
				00 00 00 00 00 00 1B 00
				06 00 0A 00 0A 32 00 01
				1B 01 06 46 46 50 00 50
				00 00 8C 1E 03 0C 0C 14
				28 04 00 00 00 00 00 00
				00 00 00 00 18 00 80 07
				01 07 07 1D 1D 00 00 07
				07 01 07 07 1D 1D 00 00
				07 04 04 39 00 07 03 00
				36 22 00 05 03 00 25 01
				00 00 04 0C EE EE 00 0C
				EE EE AA 01 3C 0C 11 11
				00 0C 66 66 AA 00 00 00
				FF FF FF FF FF FF FF FF
				51 51 51 51 CD 0D 04 83
				10 10 10 10 61 24 64 01
				1C 19 1E 1F 17 16 1A 18
				15 14 13 11 12 04 05 03
				06 FF FF FF FF FF FF FF
				FF FF FF FF FF FF FF FF
				FF FF 30 2E 2F 28 27 2D
				29 2A 2C 2B 26 23 24 25
				22 39 35 36 3A 3B 3E 3F
				31 3C 38 3D 37 00 32 01
				FF FF FF FF 00 10 00 10
				00 10 00 10 80 80 80 80
				80 80 80 80 80 80 80 80
				80 80 80 80 80 80 80 80
				80 80 80 80 80 80 80 80
				80 80 80 80 80 80 A6 9A
				8D 86 80 80 80 80 80 80
				80 80 80 80 80 80 80 80
				80 80 80 80 80 80 80 80
				80 80 80 80 80 80 80 80
				CD 14 CD 14 00 10 00 10
				00 00 1D FF FF FF FF FF
				FF FF 00 00 0F 00 44 44
				78
			];
		};

		config_12 { /* LGIT + Tianma cut 2.0 */
			pr_number     = <2298535>;
			uncover_setting = [12 52 19 05 0F 1E];
			cover_setting = [0C 13 0A 25 0A 14];
			glove_setting = [0C 13 0A 25 0A 14];
			sensor_id = <0x1>;
			disp_panel = "tianma_hx8396c2";
			module_src = <2>;
			config = [
				50 4D 45 00 4C 47 00 54
				49 41 4E 4D 41 00 08 00
				00 00 00 00 00 00 00 00
				00 00 00 00 00 00 00 00
				00 4F 01 1E 05 51 0E 9F
				05 FF 09 7D 3D 79 3D 00
				00 00 00 11 1E 1E 05 C2
				04 F8 00 2D 19 01 15 02
				F0 D2 F0 D2 6D 0D 05 46
				00 00 0F 12 5F 0F 0A 78
				00 01 01 07 04 04 32 28
				08 C8 26 26 80 80 00 00
				FF 01 64 00 05 0A 00 FF
				05 01 28 FF C0 53 5B 80
				52 19 00 40 40 32 50 00
				00 00 00 4C 04 6C 07 3C
				32 00 00 00 00 4C 04 6C
				07 1E 05 1E 04 0A 04 0A
				00 0A 04 04 00 0A 78 02
				00 7D 00 02 00 C8 00 00
				00 96 00 00 00 00 01 05
				0A 00 00 00 78 00 96 00
				32 00 00 00 00 00 00 00
				00 00 0D 00 00 14 03 0C
				0F 0A 00 4B 00 00 FF FF
				FF FF FF FF FF FF FF FF
				FF FF FF FF FF FF FF FF
				FF FF FF FF FF FF FF FF
				FF FF FF FF FF FF FF 00
				01 00 00 32 00 14 00 14
				00 64 00 64 00 10 00 10
				00 7D 00 7D 00 40 66 58
				1B 28 00 FF FF FF FF FF
				FF FF FF FF FF FF FF FF
				FF FF FF 01 00 00 00 00
				00 00 00 00 00 00 00 00
				00 00 00 00 00 00 00 00
				00 00 FF 00 FF 14 55 09
				0E 3C 0A 0F 64 64 00 00
				00 00 00 00 00 00 00 00
				00 00 00 00 00 00 00 00
				FF FF FF FF FF FF FF FF
				FF FF FF FF FF FF FF FF
				FF FF FF FF FF FF FF FF
				FF FF FF FF FF FF FF FF
				FF FF FF FF FF FF FF FF
				FF FF FF FF FF FF FF FF
				FF FF FF FF FF FF FF FF
				FF FF FF FF FF FF FF FF
				00 00 6E 00 80 04 1B 00
				00 FF 2C 01 FF FF CC 03
				E8 03 00 C0 80 04 10 0A
				18 00 79 08 08 00 01 2C
				01 06 00 06 06 07 07 00
				2C 01 01 04 03 36 00 19
				00 00 00 02 00 01 28 04
				35 00 19 00 01 00 02 00
				01 29 84 34 00 18 00 02
				00 02 00 01 2A 83 33 00
				17 00 03 00 02 00 01 2B
				83 32 00 17 00 04 00 02
				00 01 2C 83 31 00 17 00
				05 00 02 00 01 2D 03 30
				00 16 00 06 00 05 00 02
				26 03 2F 00 16 00 07 00
				05 00 02 27 05 05 05 05
				05 05 05 05 05 05 05 05
				05 05 05 05 05 00 00 00
				00 00 00 00 00 00 00 00
				00 00 00 00 00 00 1B 00
				06 00 0A 00 0A 32 00 01
				1B 01 06 46 46 50 00 50
				00 00 8C 1E 03 0C 0C 14
				28 04 00 00 00 00 00 00
				00 00 00 00 18 00 80 07
				01 07 07 1D 1D 00 00 07
				07 01 07 07 1D 1D 00 00
				07 04 04 39 00 07 03 00
				36 22 00 05 03 00 25 01
				00 00 04 0C EE EE 00 0C
				EE EE AA 01 28 0C 11 11
				00 0C 66 66 AA 00 00 00
				FF FF FF FF FF FF FF FF
				51 51 51 51 CD 0D 04 83
				10 10 10 10 61 24 64 01
				1C 19 1E 1F 17 16 1A 18
				15 14 13 11 12 04 05 03
				06 FF FF FF FF FF FF FF
				FF FF FF FF FF FF FF FF
				FF FF 30 2E 2F 28 27 2D
				29 2A 2C 2B 26 23 24 25
				22 39 35 36 3A 3B 3E 3F
				31 3C 38 3D 37 00 32 01
				FF FF FF FF 00 10 00 10
				00 10 00 10 80 80 80 80
				80 80 80 80 80 80 80 80
				80 80 80 80 80 80 80 80
				80 80 80 80 80 80 80 80
				80 80 80 80 80 80 A6 9A
				8D 86 80 80 80 80 80 80
				80 80 80 80 80 80 80 80
				80 80 80 80 80 80 80 80
				80 80 80 80 80 80 80 80
				CD 14 CD 14 00 10 00 10
				00 00 1D FF FF FF FF FF
				FF FF 00 00 0F 00 44 44
				78
			];
		};

		config_11 { /* LGIT + Tianma */
			pr_number     = <2298535>;
			uncover_setting = [12 52 19 05 0F 1E];
			cover_setting = [0C 13 0A 25 0A 14];
			glove_setting = [0C 13 0A 25 0A 14];
			sensor_id = <0x1>;
			disp_panel = "tia";
			module_src = <2>;
			config = [
				50 4D 45 00 4C 47 00 54
				49 41 4E 4D 41 00 08 10
				00 00 00 00 00 00 00 00
				00 00 00 00 00 00 00 00
				00 4F 01 1E 05 51 0E 9F
				05 FF 09 7D 3D 79 3D 00
				00 00 00 11 1E 1E 05 C2
				04 F8 00 2D 19 01 15 02
				F0 D2 F0 D2 6D 0D 05 46
				00 00 0F 12 5F 0F 0A 78
				00 01 01 07 04 04 32 28
				08 C8 26 26 80 80 00 00
				FF 01 64 00 05 0A 00 FF
				05 01 28 FF C0 53 5B 80
				52 19 00 40 40 32 50 00
				00 00 00 4C 04 6C 07 3C
				32 00 00 00 00 4C 04 6C
				07 1E 05 1E 04 0A 04 0A
				00 0A 04 04 00 0A 78 02
				00 7D 00 02 00 C8 00 00
				00 96 00 00 00 00 01 05
				0A 00 00 00 78 00 96 00
				32 00 00 00 00 00 00 00
				00 00 0D 00 00 14 03 0C
				0F 0A 00 4B 00 00 FF FF
				FF FF FF FF FF FF FF FF
				FF FF FF FF FF FF FF FF
				FF FF FF FF FF FF FF FF
				FF FF FF FF FF FF FF 00
				01 00 00 32 00 14 00 14
				00 64 00 64 00 10 00 10
				00 7D 00 7D 00 40 66 58
				1B 28 00 FF FF FF FF FF
				FF FF FF FF FF FF FF FF
				FF FF FF 01 00 00 00 00
				00 00 00 00 00 00 00 00
				00 00 00 00 00 00 00 00
				00 00 FF 00 FF 14 55 09
				0E 3C 0A 0F 64 64 00 00
				00 00 00 00 00 00 00 00
				00 00 00 00 00 00 00 00
				FF FF FF FF FF FF FF FF
				FF FF FF FF FF FF FF FF
				FF FF FF FF FF FF FF FF
				FF FF FF FF FF FF FF FF
				FF FF FF FF FF FF FF FF
				FF FF FF FF FF FF FF FF
				FF FF FF FF FF FF FF FF
				FF FF FF FF FF FF FF FF
				00 00 6E 00 80 04 1B 00
				00 FF 2C 01 FF FF CC 03
				E8 03 00 C0 80 04 10 0A
				18 00 79 08 08 00 01 2C
				01 06 00 06 06 07 07 00
				2C 01 01 04 03 36 00 19
				00 00 00 02 00 01 28 04
				35 00 19 00 01 00 02 00
				01 29 84 34 00 18 00 02
				00 02 00 01 2A 83 33 00
				17 00 03 00 02 00 01 2B
				83 32 00 17 00 04 00 02
				00 01 2C 83 31 00 17 00
				05 00 02 00 01 2D 03 30
				00 16 00 06 00 05 00 02
				26 03 2F 00 16 00 07 00
				05 00 02 27 05 05 05 05
				05 05 05 05 05 05 05 05
				05 05 05 05 05 00 00 00
				00 00 00 00 00 00 00 00
				00 00 00 00 00 00 1B 00
				06 00 0A 00 0A 32 00 01
				1B 01 06 46 46 50 00 50
				00 00 8C 1E 03 0C 0C 14
				28 04 00 00 00 00 00 00
				00 00 00 00 18 00 80 07
				01 07 07 1D 1D 00 00 07
				07 01 07 07 1D 1D 00 00
				07 04 04 39 00 07 03 00
				36 22 00 05 03 00 25 01
				00 00 04 0C EE EE 00 0C
				EE EE AA 01 28 0C 11 11
				00 0C 66 66 AA 00 00 00
				FF FF FF FF FF FF FF FF
				51 51 51 51 CD 0D 04 83
				10 10 10 10 61 24 64 01
				1C 19 1E 1F 17 16 1A 18
				15 14 13 11 12 04 05 03
				06 FF FF FF FF FF FF FF
				FF FF FF FF FF FF FF FF
				FF FF 30 2E 2F 28 27 2D
				29 2A 2C 2B 26 23 24 25
				22 39 35 36 3A 3B 3E 3F
				31 3C 38 3D 37 00 32 01
				FF FF FF FF 00 10 00 10
				00 10 00 10 80 80 80 80
				80 80 80 80 80 80 80 80
				80 80 80 80 80 80 80 80
				80 80 80 80 80 80 80 80
				80 80 80 80 80 80 A6 9A
				8D 86 80 80 80 80 80 80
				80 80 80 80 80 80 80 80
				80 80 80 80 80 80 80 80
				80 80 80 80 80 80 80 80
				CD 14 CD 14 00 10 00 10
				00 00 1D FF FF FF FF FF
				FF FF 00 00 0F 00 44 44
				78
			];
		};

		config_10 { /* YFO R1 */
			pr_number     = <2298535>;
//			uncover_setting = [0F 5B 19 15 0C];
//			cover_setting = [0C 17 0C 25 0A];
//			glove_setting = [0C 17 0C 25 0A];
			sensor_id = <0x0>;
			module_src = <0>;
			config = [
				4F 32 00 07 00 00 00 00
				00 00 00 00 00 00 00 00
				00 00 00 00 00 00 00 00
				00 00 00 00 00 00 00 00
				00 4F 03 1E 05 51 0E 9F
				05 FF 09 00 40 00 40 00
				00 00 00 11 1E 1E 05 59
				08 E3 01 2D 16 01 17 01
				F0 D2 F0 D2 25 0D 05 8C
				00 00 0C 0F 80 0F 0A 78
				00 01 01 07 04 04 0A C0
				19 64 26 26 80 80 00 00
				C8 03 C8 00 0D 14 00 FF
				0F 01 28 C0 C0 53 5B 80
				5B 19 01 40 40 32 50 00
				00 00 00 4C 04 6C 07 3C
				32 00 00 00 00 4C 04 6C
				07 1E 05 1E 04 0A 04 0A
				00 0A 04 04 00 0A 78 02
				00 7D 00 02 00 C8 00 00
				00 96 00 00 00 00 01 15
				0A 00 00 00 78 00 96 00
				32 00 00 00 00 00 00 00
				00 00 0D 00 00 14 03 0C
				0F 0A 00 4B 00 00 FF FF
				FF FF FF FF FF FF FF FF
				FF FF FF FF FF FF FF FF
				FF FF FF FF FF FF FF FF
				FF FF FF FF FF FF FF 00
				01 00 00 32 00 14 00 14
				00 64 00 64 00 10 00 10
				00 7D 00 7D 00 40 66 58
				1B 28 00 FF FF FF FF FF
				FF FF FF FF FF FF FF FF
				FF FF FF 01 00 00 00 00
				00 00 00 00 00 00 00 00
				00 00 00 00 00 00 00 00
				00 00 FF 00 FF 14 55 09
				0E 3C 0A 0F 64 64 00 00
				00 00 00 00 00 00 00 00
				00 00 00 00 00 00 00 00
				FF FF FF FF FF FF FF FF
				FF FF FF FF FF FF FF FF
				FF FF FF FF FF FF FF FF
				FF FF FF FF FF FF FF FF
				FF FF FF FF FF FF FF FF
				FF FF FF FF FF FF FF FF
				FF FF FF FF FF FF FF FF
				FF FF FF FF FF FF FF FF
				00 00 C8 00 80 04 1B 00
				00 FF 2C 01 FF FF CC 03
				E8 03 00 C0 80 04 10 0A
				18 00 79 08 08 00 01 2C
				01 06 00 03 03 07 07 03
				2C 01 01 04 03 29 00 12
				00 00 00 03 00 01 25 03
				28 00 12 00 02 00 03 00
				01 27 82 26 00 11 00 04
				00 03 00 01 28 82 25 00
				11 00 06 00 07 00 02 24
				02 24 00 10 00 08 00 07
				00 02 25 82 23 00 10 00
				0A 00 07 00 02 26 02 22
				00 0F 00 0B 00 07 00 02
				27 02 21 00 0F 00 11 00
				04 00 01 25 04 05 04 05
				05 04 04 04 04 04 05 04
				04 04 04 04 04 00 00 00
				00 00 00 00 00 00 00 00
				00 00 00 00 00 00 2B 00
				06 00 A6 00 14 64 00 01
				1B 02 06 32 32 50 00 50
				00 50 50 1E 03 0C 0C 14
				28 04 00 00 00 00 00 00
				00 00 00 00 11 00 00 07
				01 07 07 1D 1D 00 00 07
				07 01 07 07 1D 1D 00 00
				07 04 04 50 00 07 03 00
				29 22 00 05 03 00 25 01
				00 00 00 0C 00 00 00 0C
				00 00 00 01 23 0C 00 00
				00 0C 00 00 AA 00 00 00
				FF FF FF FF FF FF FF FF
				51 51 51 51 CD 0D 04 83
				10 10 10 10 61 24 64 01
				1C 19 1E 1F 17 16 1A 18
				15 10 11 0B 0F 13 0E 12
				0D FF FF FF FF FF FF FF
				FF FF FF FF FF FF FF FF
				FF FF 30 2E 2F 28 27 2D
				29 2A 2C 2B 26 23 24 25
				22 39 35 36 3A 3B 3C 3F
				31 3E 38 3D 37 00 32 01
				FF FF FF FF 00 10 00 10
				00 10 00 10 80 80 80 80
				80 80 80 80 80 80 80 80
				80 80 80 80 80 80 80 80
				80 80 80 80 80 80 80 80
				80 80 80 80 80 80 80 80
				80 80 80 80 80 80 80 80
				80 80 80 80 80 80 80 80
				80 80 80 80 80 80 80 80
				80 80 80 80 80 80 80 80
				00 10 00 10 00 10 00 10
				00 00 FF FF FF FF 1D FF
				FF FF 00 00 0F 00 00 00
				A0
			];
		};

		config_9 { /* YFO R2 + Sharp cut 2.0 */
			pr_number     = <2235544>;
			uncover_setting = [12 5A 19 05 0F 28];
			cover_setting = [0C 13 0A 25 0A 14];
			glove_setting = [0C 13 0A 25 0A 14];
			sensor_id = <0x2>;
			disp_panel = "sharp_hx8396c2";
			module_src = <1>;
			config = [
				50 4D 45 00 59 46 4F 00
				53 48 41 52 50 00 05 00
				00 00 00 00 00 00 00 00
				00 00 00 00 00 00 00 00
				00 4F 01 28 05 51 0E 9F
				05 FF 09 7D 3D 79 3D 00
				00 00 00 11 1E 1E 05 6B
				08 60 01 2D 17 02 14 02
				F0 D2 F0 D2 6D 0D 05 46
				00 00 0F 12 5F 0F 0A 78
				00 01 01 07 04 04 32 28
				08 C8 26 26 80 80 00 00
				FF C0 53 5B 80 5A 19 00
				40 40 32 50 00 00 00 00
				4C 04 6C 07 3C 32 00 00
				00 00 4C 04 6C 07 1E 05
				1E 04 0A 04 0A 00 0A 04
				04 00 0A 78 02 00 7D 00
				02 00 C8 00 00 00 96 00
				00 00 00 01 05 0A 00 00
				00 78 00 96 00 32 00 00
				00 00 00 00 00 00 00 0D
				00 00 14 03 0C 0F 0A 00
				4B 00 00 FF FF FF FF FF
				FF FF FF FF FF FF FF FF
				FF FF FF FF FF FF FF FF
				FF FF FF FF FF FF FF FF
				FF FF FF FF 00 01 00 00
				32 00 14 00 14 00 64 00
				64 00 10 00 10 00 7D 00
				7D 00 40 66 58 1B 28 00
				FF FF FF FF FF FF FF FF
				FF FF FF FF FF FF FF FF
				01 00 00 00 00 00 00 00
				00 00 00 00 00 00 00 00
				00 00 00 00 00 00 00 FF
				00 FF 14 55 09 0E 3C 0A
				0F 64 64 00 00 00 00 00
				00 00 00 00 00 00 00 00
				00 00 00 00 00 FF FF FF
				FF FF FF FF FF FF FF FF
				FF FF FF FF FF FF FF FF
				FF FF FF FF FF FF FF FF
				FF FF FF FF FF FF FF FF
				FF FF FF FF FF FF FF FF
				FF FF FF FF FF FF FF FF
				FF FF FF FF FF FF FF FF
				FF FF FF FF FF 00 00 6E
				00 80 04 1B 00 00 FF 2C
				01 FF FF CC 03 E8 03 00
				C0 80 04 10 0A 18 00 79
				08 08 00 01 2C 01 06 00
				03 03 07 07 03 2C 01 01
				04 03 36 00 19 00 00 00
				02 00 01 28 04 35 00 19
				00 01 00 02 00 01 29 84
				34 00 18 00 02 00 02 00
				01 2A 83 33 00 17 00 03
				00 02 00 01 2B 83 32 00
				17 00 04 00 02 00 01 2C
				83 31 00 17 00 05 00 02
				00 01 2D 03 30 00 16 00
				06 00 05 00 02 26 03 2F
				00 16 00 07 00 05 00 02
				27 06 06 06 06 06 06 06
				06 06 06 06 05 05 05 05
				06 05 00 00 00 00 00 00
				00 00 00 00 00 00 00 00
				00 00 00 1B 00 06 00 A6
				00 14 64 00 01 1B 02 06
				46 46 50 00 50 00 78 78
				1E 03 0C 0C 14 28 04 00
				00 00 00 00 00 00 00 00
				00 18 00 80 07 01 07 07
				1D 1D 00 00 07 07 01 07
				07 1D 1D 00 00 07 04 04
				52 00 07 03 00 36 22 00
				05 03 00 25 01 00 00 04
				0C 00 00 00 0C 00 00 00
				01 3C 0C 11 11 00 0C 66
				66 AA 00 00 00 FF FF FF
				FF FF FF FF FF 51 51 51
				51 CD 0D 04 83 10 10 10
				10 61 24 64 01 1C 19 1E
				1F 17 16 1A 18 15 14 13
				11 12 04 05 03 06 FF FF
				FF FF FF FF FF FF FF FF
				FF FF FF FF FF FF FF 30
				2E 2F 28 27 2D 29 2A 2C
				2B 26 23 24 25 22 39 35
				3C 3A 3B 3E 3F 31 36 38
				3D 37 00 32 01 FF FF FF
				FF 00 10 00 10 00 10 00
				10 80 80 80 80 80 80 80
				80 80 80 80 80 80 80 80
				80 80 80 80 80 80 80 80
				80 80 80 80 80 80 80 80
				80 80 80 A6 9A 8D 86 80
				80 80 80 80 80 80 80 80
				80 80 80 80 80 80 80 80
				80 80 80 80 80 80 80 80
				80 80 80 80 80 CD 14 CD
				14 00 10 00 10 00 00 1D
				FF FF FF FF FF FF FF 00
				00 0F 00 44 44
			];
		};

		config_8 { /* YFO R2 + Sharp */
			pr_number     = <2235544>;
			uncover_setting = [12 5A 19 05 0F];
			cover_setting = [0C 17 0C 25 0A];
			glove_setting = [0C 17 0C 25 0A];
			sensor_id = <0x2>;
			disp_panel = "sharp";
			module_src = <1>;
			config = [
				50 4D 45 00 59 46 4F 00
				08 00 00 00 00 00 00 00
				00 00 00 00 00 00 00 00
				00 00 00 00 00 00 00 00
				00 4F 03 14 05 51 0E 70
				08 00 0F 7D 3D 79 3D 00
				00 00 00 11 1E 1E 05 6B
				08 60 01 2D 17 02 14 02
				F0 D2 F0 D2 6D 0D 05 46
				00 00 0F 12 8C 0F 0A 78
				00 01 01 07 04 04 32 28
				08 C8 26 26 80 80 00 00
				FF C0 53 5B 80 5A 19 01
				40 40 32 50 00 00 00 00
				4C 04 6C 07 3C 32 00 00
				00 00 4C 04 6C 07 1E 05
				1E 04 0A 04 0A 00 0A 04
				04 00 0A 78 02 00 7D 00
				02 00 C8 00 00 00 96 00
				00 00 00 01 05 0A 00 00
				00 78 00 96 00 32 00 00
				00 00 00 00 00 00 00 0D
				00 00 14 03 0C 0F 0A 00
				4B 00 00 FF FF FF FF FF
				FF FF FF FF FF FF FF FF
				FF FF FF FF FF FF FF FF
				FF FF FF FF FF FF FF FF
				FF FF FF FF 00 01 00 00
				32 00 14 00 14 00 64 00
				64 00 10 00 10 00 7D 00
				7D 00 40 66 58 1B 28 00
				FF FF FF FF FF FF FF FF
				FF FF FF FF FF FF FF FF
				01 00 00 00 00 00 00 00
				00 00 00 00 00 00 00 00
				00 00 00 00 00 00 00 FF
				00 FF 14 55 09 0E 3C 0A
				0F 64 64 00 00 00 00 00
				00 00 00 00 00 00 00 00
				00 00 00 00 00 FF FF FF
				FF FF FF FF FF FF FF FF
				FF FF FF FF FF FF FF FF
				FF FF FF FF FF FF FF FF
				FF FF FF FF FF FF FF FF
				FF FF FF FF FF FF FF FF
				FF FF FF FF FF FF FF FF
				FF FF FF FF FF FF FF FF
				FF FF FF FF FF 00 00 B7
				00 80 04 1B 00 00 FF 2C
				01 FF FF CC 03 E8 03 00
				C0 80 04 10 0A 18 00 79
				08 08 00 01 2C 01 06 00
				03 03 07 07 03 2C 01 01
				04 83 36 00 19 00 00 00
				02 00 01 28 04 35 00 19
				00 01 00 02 00 01 29 04
				34 00 18 00 02 00 02 00
				01 2A 03 33 00 17 00 03
				00 02 00 01 2B 03 32 00
				17 00 04 00 02 00 01 2C
				83 31 00 17 00 05 00 02
				00 01 2D 83 30 00 16 00
				06 00 05 00 02 26 83 2F
				00 16 00 07 00 05 00 02
				27 06 06 06 06 06 06 06
				06 06 06 06 05 05 05 05
				06 05 00 00 00 00 00 00
				00 00 00 00 00 00 00 00
				00 00 00 1B 00 06 00 A6
				00 14 64 00 01 1B 02 06
				46 46 50 00 50 00 64 64
				1E 03 0C 0C 14 28 04 00
				00 00 00 00 00 00 00 00
				00 18 00 80 07 01 07 07
				1D 1D 00 00 07 07 01 07
				07 1D 1D 00 00 07 04 04
				4A 00 07 03 00 36 22 00
				05 03 00 25 01 00 00 04
				0C 00 00 00 0C 00 00 00
				01 3C 0C 11 11 00 0C 66
				66 AA 00 00 00 FF FF FF
				FF FF FF FF FF 51 51 51
				51 CD 0D 04 83 10 10 10
				10 61 24 64 01 1C 19 1E
				1F 17 16 1A 18 15 14 13
				11 12 04 05 03 06 FF FF
				FF FF FF FF FF FF FF FF
				FF FF FF FF FF FF FF 30
				2E 2F 28 27 2D 29 2A 2C
				2B 26 23 24 25 22 39 35
				3C 3A 3B 3E 3F 31 36 38
				3D 37 00 32 01 FF FF FF
				FF 00 10 00 10 00 10 00
				10 80 80 80 80 80 80 80
				80 80 80 80 80 80 80 80
				80 80 80 80 80 80 80 80
				80 80 80 80 80 80 80 80
				80 80 80 80 80 80 80 80
				80 80 80 80 80 80 80 80
				80 80 80 80 80 80 80 80
				80 80 80 80 80 80 80 80
				80 80 80 80 80 00 10 00
				10 00 10 00 10 00 00 1D
				FF FF FF FF FF FF FF 00
				00 0F 00 44 44
			];
		};

		config_7 { /* LGIT + Sharp (cut 2.0 only) */
			pr_number     = <2235544>;
			uncover_setting = [12 52 19 05 0F 28];
			cover_setting = [0C 13 0A 25 0A 14];
			glove_setting = [0C 13 0A 25 0A 14];
			sensor_id = <0x1>;
			disp_panel = "sharp";
			module_src = <3>;
			config = [
				50 4D 45 00 54 54 00 05
				00 00 00 00 00 00 00 00
				00 00 00 00 00 00 00 00
				00 00 00 00 00 00 00 00
				00 4F 01 28 05 51 0E 9F
				05 FF 09 7D 3D 79 3D 00
				00 00 00 11 1E 1E 05 C2
				04 F8 00 2D 19 01 15 02
				F0 D2 F0 D2 6D 0D 05 46
				00 00 0F 12 5F 0F 0A 78
				00 01 01 07 04 04 32 28
				08 C8 26 26 80 80 00 00
				FF C0 53 5B 80 52 19 00
				40 40 32 50 00 00 00 00
				4C 04 6C 07 3C 32 00 00
				00 00 4C 04 6C 07 1E 05
				1E 04 0A 04 0A 00 0A 04
				04 00 0A 78 02 00 7D 00
				02 00 C8 00 00 00 96 00
				00 00 00 01 05 0A 00 00
				00 78 00 96 00 32 00 00
				00 00 00 00 00 00 00 0D
				00 00 14 03 0C 0F 0A 00
				4B 00 00 FF FF FF FF FF
				FF FF FF FF FF FF FF FF
				FF FF FF FF FF FF FF FF
				FF FF FF FF FF FF FF FF
				FF FF FF FF 00 01 00 00
				32 00 14 00 14 00 64 00
				64 00 10 00 10 00 7D 00
				7D 00 40 66 58 1B 28 00
				FF FF FF FF FF FF FF FF
				FF FF FF FF FF FF FF FF
				01 00 00 00 00 00 00 00
				00 00 00 00 00 00 00 00
				00 00 00 00 00 00 00 FF
				00 FF 14 55 09 0E 3C 0A
				0F 64 64 00 00 00 00 00
				00 00 00 00 00 00 00 00
				00 00 00 00 00 FF FF FF
				FF FF FF FF FF FF FF FF
				FF FF FF FF FF FF FF FF
				FF FF FF FF FF FF FF FF
				FF FF FF FF FF FF FF FF
				FF FF FF FF FF FF FF FF
				FF FF FF FF FF FF FF FF
				FF FF FF FF FF FF FF FF
				FF FF FF FF FF 00 00 6E
				00 80 04 1B 00 00 FF 2C
				01 FF FF CC 03 E8 03 00
				C0 80 04 10 0A 18 00 79
				08 08 00 01 2C 01 06 00
				06 06 07 07 00 2C 01 01
				04 03 36 00 19 00 00 00
				02 00 01 28 84 35 00 19
				00 01 00 02 00 01 29 04
				34 00 18 00 02 00 02 00
				01 2A 83 33 00 17 00 03
				00 02 00 01 2B 83 32 00
				17 00 04 00 02 00 01 2C
				03 31 00 17 00 05 00 02
				00 01 2D 83 30 00 16 00
				06 00 05 00 02 26 03 2F
				00 16 00 07 00 05 00 02
				27 05 05 05 05 05 05 05
				05 05 05 05 05 05 05 05
				05 05 00 00 00 00 00 00
				00 00 00 00 00 00 00 00
				00 00 00 1B 00 06 00 A6
				00 14 64 00 01 1B 02 06
				46 46 50 00 50 00 78 78
				1E 03 0C 0C 14 28 04 00
				00 00 00 00 00 00 00 00
				00 18 00 80 07 01 07 07
				1D 1D 00 00 07 07 01 07
				07 1D 1D 00 00 07 04 04
				52 00 07 03 00 36 22 00
				05 03 00 25 01 00 00 04
				0C EE EE 00 0C EE EE AA
				01 3C 0C 11 11 00 0C 66
				66 AA 00 00 00 FF FF FF
				FF FF FF FF FF 51 51 51
				51 CD 0D 04 83 10 10 10
				10 61 24 64 01 1C 19 1E
				1F 17 16 1A 18 15 14 13
				11 12 04 05 03 06 FF FF
				FF FF FF FF FF FF FF FF
				FF FF FF FF FF FF FF 30
				2E 2F 28 27 2D 29 2A 2C
				2B 26 23 24 25 22 39 35
				36 3A 3B 3E 3F 31 3C 38
				3D 37 00 32 01 FF FF FF
				FF 00 10 00 10 00 10 00
				10 80 80 80 80 80 80 80
				80 80 80 80 80 80 80 80
				80 80 80 80 80 80 80 80
				80 80 80 80 80 80 80 80
				80 80 80 A6 9A 8D 86 80
				80 80 80 80 80 80 80 80
				80 80 80 80 80 80 80 80
				80 80 80 80 80 80 80 80
				80 80 80 80 80 CD 14 CD
				14 00 10 00 10 00 00 1D
				FF FF FF FF FF FF FF 00
				00 0F 00 44 44
			];
		};

		config_6 { /* LGIT + Tianma cut 2.0 */
			pr_number     = <2235544>;
			uncover_setting = [12 52 19 05 0F 1E];
			cover_setting = [0C 13 0A 25 0A 14];
			glove_setting = [0C 13 0A 25 0A 14];
			sensor_id = <0x1>;
			disp_panel = "tianma_hx8396c2";
			module_src = <2>;
			config = [
				50 4D 45 00 4C 47 00 54
				49 4E 41 4D 41 00 05 00
				00 00 00 00 00 00 00 00
				00 00 00 00 00 00 00 00
				00 4F 01 1E 05 51 0E 9F
				05 FF 09 7D 3D 79 3D 00
				00 00 00 11 1E 1E 05 C2
				04 F8 00 2D 19 01 15 02
				F0 D2 F0 D2 6D 0D 05 46
				00 00 0F 12 5F 0F 0A 78
				00 01 01 07 04 04 32 28
				08 C8 26 26 80 80 00 00
				FF C0 53 5B 80 52 19 00
				40 40 32 50 00 00 00 00
				4C 04 6C 07 3C 32 00 00
				00 00 4C 04 6C 07 1E 05
				1E 04 0A 04 0A 00 0A 04
				04 00 0A 78 02 00 7D 00
				02 00 C8 00 00 00 96 00
				00 00 00 01 05 0A 00 00
				00 78 00 96 00 32 00 00
				00 00 00 00 00 00 00 0D
				00 00 14 03 0C 0F 0A 00
				4B 00 00 FF FF FF FF FF
				FF FF FF FF FF FF FF FF
				FF FF FF FF FF FF FF FF
				FF FF FF FF FF FF FF FF
				FF FF FF FF 00 01 00 00
				32 00 14 00 14 00 64 00
				64 00 10 00 10 00 7D 00
				7D 00 40 66 58 1B 28 00
				FF FF FF FF FF FF FF FF
				FF FF FF FF FF FF FF FF
				01 00 00 00 00 00 00 00
				00 00 00 00 00 00 00 00
				00 00 00 00 00 00 00 FF
				00 FF 14 55 09 0E 3C 0A
				0F 64 64 00 00 00 00 00
				00 00 00 00 00 00 00 00
				00 00 00 00 00 FF FF FF
				FF FF FF FF FF FF FF FF
				FF FF FF FF FF FF FF FF
				FF FF FF FF FF FF FF FF
				FF FF FF FF FF FF FF FF
				FF FF FF FF FF FF FF FF
				FF FF FF FF FF FF FF FF
				FF FF FF FF FF FF FF FF
				FF FF FF FF FF 00 00 6E
				00 80 04 1B 00 00 FF 2C
				01 FF FF CC 03 E8 03 00
				C0 80 04 10 0A 18 00 79
				08 08 00 01 2C 01 06 00
				06 06 07 07 00 2C 01 01
				04 03 36 00 19 00 00 00
				02 00 01 28 04 35 00 19
				00 01 00 02 00 01 29 84
				34 00 18 00 02 00 02 00
				01 2A 83 33 00 17 00 03
				00 02 00 01 2B 83 32 00
				17 00 04 00 02 00 01 2C
				83 31 00 17 00 05 00 02
				00 01 2D 03 30 00 16 00
				06 00 05 00 02 26 03 2F
				00 16 00 07 00 05 00 02
				27 05 05 05 05 05 05 05
				05 05 05 05 05 05 05 05
				05 05 00 00 00 00 00 00
				00 00 00 00 00 00 00 00
				00 00 00 1B 00 06 00 A6
				00 14 64 00 01 1B 02 06
				46 46 50 00 50 00 78 78
				1E 03 0C 0C 14 28 04 00
				00 00 00 00 00 00 00 00
				00 18 00 80 07 01 07 07
				1D 1D 00 00 07 07 01 07
				07 1D 1D 00 00 07 04 04
				50 00 07 03 00 36 22 00
				05 0B 00 22 02 00 00 04
				0C 00 00 00 0C 00 00 00
				01 28 0C 11 11 00 0C 66
				66 AA 00 00 00 FF FF FF
				FF FF FF FF FF 51 51 51
				51 CD 0D 04 83 10 10 10
				10 61 24 64 01 1C 19 1E
				1F 17 16 1A 18 15 14 13
				11 12 04 05 03 06 FF FF
				FF FF FF FF FF FF FF FF
				FF FF FF FF FF FF FF 30
				2E 2F 28 27 2D 29 2A 2C
				2B 26 23 24 25 22 39 35
				36 3A 3B 3E 3F 31 3C 38
				3D 37 00 32 01 FF FF FF
				FF 00 10 00 10 00 10 00
				10 80 80 80 80 80 80 80
				80 80 80 80 80 80 80 80
				80 80 80 80 80 80 80 80
				80 80 80 80 80 80 80 80
				80 80 80 A6 9A 8D 86 80
				80 80 80 80 80 80 80 80
				80 80 80 80 80 80 80 80
				80 80 80 80 80 80 80 80
				80 80 80 80 80 CD 14 CD
				14 00 10 00 10 00 00 1D
				FF FF FF FF FF FF FF 00
				00 0F 00 44 44
			];
		};

		config_5 { /* LGIT + Tianma */
			pr_number     = <2235544>;
			uncover_setting = [12 52 19 05 0F];
			cover_setting = [0C 17 0C 25 0A];
			glove_setting = [0C 17 0C 25 0A];
			sensor_id = <0x1>;
			disp_panel = "tia";
			module_src = <2>;
			config = [
				50 4D 45 00 4C 47 00 05
				00 00 00 00 00 00 00 00
				00 00 00 00 00 00 00 00
				00 00 00 00 00 00 00 00
				00 4F 03 14 05 51 0E 70
				08 00 0F 7D 3D 79 3D 00
				00 00 00 11 1E 1E 05 C2
				04 F8 00 2D 19 01 15 02
				F0 D2 F0 D2 6D 0D 05 46
				00 00 0F 12 8C 0F 0A 78
				00 01 01 07 04 04 32 28
				08 C8 26 26 80 80 00 00
				FF C0 53 5B 80 52 19 01
				40 40 32 50 00 00 00 00
				4C 04 6C 07 3C 32 00 00
				00 00 4C 04 6C 07 1E 05
				1E 04 0A 04 0A 00 0A 04
				04 00 0A 78 02 00 7D 00
				02 00 C8 00 00 00 96 00
				00 00 00 01 05 0A 00 00
				00 78 00 96 00 32 00 00
				00 00 00 00 00 00 00 0D
				00 00 14 03 0C 0F 0A 00
				4B 00 00 FF FF FF FF FF
				FF FF FF FF FF FF FF FF
				FF FF FF FF FF FF FF FF
				FF FF FF FF FF FF FF FF
				FF FF FF FF 00 01 00 00
				32 00 14 00 14 00 64 00
				64 00 10 00 10 00 7D 00
				7D 00 40 66 58 1B 28 00
				FF FF FF FF FF FF FF FF
				FF FF FF FF FF FF FF FF
				01 00 00 00 00 00 00 00
				00 00 00 00 00 00 00 00
				00 00 00 00 00 00 00 FF
				00 FF 14 55 09 0E 3C 0A
				0F 64 64 00 00 00 00 00
				00 00 00 00 00 00 00 00
				00 00 00 00 00 FF FF FF
				FF FF FF FF FF FF FF FF
				FF FF FF FF FF FF FF FF
				FF FF FF FF FF FF FF FF
				FF FF FF FF FF FF FF FF
				FF FF FF FF FF FF FF FF
				FF FF FF FF FF FF FF FF
				FF FF FF FF FF FF FF FF
				FF FF FF FF FF 00 00 BA
				00 80 04 1B 00 00 FF 2C
				01 FF FF CC 03 E8 03 00
				C0 80 04 10 0A 18 00 79
				08 08 00 01 2C 01 06 00
				06 06 07 07 00 2C 01 01
				04 03 36 00 19 00 00 00
				02 00 01 28 04 35 00 19
				00 01 00 02 00 01 29 04
				34 00 18 00 02 00 02 00
				01 2A 83 33 00 17 00 03
				00 02 00 01 2B 03 32 00
				17 00 04 00 02 00 01 2C
				83 31 00 17 00 05 00 02
				00 01 2D 83 30 00 16 00
				06 00 05 00 02 26 83 2F
				00 16 00 07 00 05 00 02
				27 05 05 05 05 05 05 05
				05 05 05 05 05 05 05 05
				05 05 00 00 00 00 00 00
				00 00 00 00 00 00 00 00
				00 00 00 1B 00 06 00 A6
				00 14 64 00 01 1B 02 06
				32 32 50 00 50 00 50 50
				1E 03 0C 0C 14 28 04 00
				00 00 00 00 00 00 00 00
				00 18 00 80 07 01 07 07
				1D 1D 00 00 07 07 01 07
				07 1D 1D 00 00 07 04 04
				50 00 07 03 00 36 22 00
				05 03 00 25 01 00 00 04
				0C EE EE 00 0C EE EE AA
				01 28 0C 11 11 00 0C 66
				66 AA 00 00 00 FF FF FF
				FF FF FF FF FF 51 51 51
				51 CD 0D 04 83 10 10 10
				10 61 24 64 01 1C 19 1E
				1F 17 16 1A 18 15 14 13
				11 12 04 05 03 06 FF FF
				FF FF FF FF FF FF FF FF
				FF FF FF FF FF FF FF 30
				2E 2F 28 27 2D 29 2A 2C
				2B 26 23 24 25 22 39 35
				36 3A 3B 3E 3F 31 3C 38
				3D 37 00 32 01 FF FF FF
				FF 00 10 00 10 00 10 00
				10 80 80 80 80 80 80 80
				80 80 80 80 80 80 80 80
				80 80 80 80 80 80 80 80
				80 80 80 80 80 80 80 80
				80 80 80 80 80 80 80 80
				80 80 80 80 80 80 80 80
				80 80 80 80 80 80 80 80
				80 80 80 80 80 80 80 80
				80 80 80 80 80 00 10 00
				10 00 10 00 10 00 00 1D
				FF FF FF FF FF FF FF 00
				00 0F 00 44 44
			];
		};

		config_4 { /* LGIT + Tianma*/
			pr_number     = <2093014>;
			uncover_setting = [12 52 19 05 0F];
			cover_setting = [0C 17 0C 25 0A];
			glove_setting = [0C 17 0C 25 0A];
			sensor_id = <0x1>;
			config = [
				50 4D 45 00 4C 47 00 05
				00 00 00 00 00 00 00 00
				00 00 00 00 00 00 00 00
				00 00 00 00 00 00 00 00
				00 4F 03 14 05 51 0E 70
				08 00 0F 7D 3D 79 3D 00
				00 00 00 11 1E 1E 05 C2
				04 F8 00 2D 19 01 15 02
				F0 D2 F0 D2 6D 0D 05 46
				00 00 0F 12 8C 0F 0A 78
				00 01 01 07 04 04 32 28
				08 C8 26 26 80 80 00 00
				FF C0 53 5B 80 52 19 01
				40 40 32 50 00 00 00 00
				4C 04 6C 07 3C 32 00 00
				00 00 4C 04 6C 07 1E 05
				1E 04 0A 04 0A 00 0A 04
				04 00 0A 78 02 00 7D 00
				02 00 C8 00 00 00 96 00
				00 00 00 01 05 0A 00 00
				00 78 00 96 00 32 00 00
				00 00 00 00 00 00 00 0D
				00 00 14 03 0C 0F 0A 00
				4B 00 00 FF FF FF FF FF
				FF FF FF FF FF FF FF FF
				FF FF FF FF FF FF FF FF
				FF FF FF FF FF FF FF FF
				FF FF FF FF 00 01 00 00
				32 00 14 00 14 00 64 00
				64 00 10 00 10 00 7D 00
				7D 00 40 66 58 1B 28 00
				FF FF FF FF FF FF FF FF
				FF FF FF FF FF FF FF FF
				01 00 00 00 00 00 00 00
				00 00 00 00 00 00 00 00
				00 00 00 00 00 00 00 FF
				00 FF 14 55 09 0E 3C 0A
				0F 64 64 00 00 00 00 00
				00 00 00 00 00 00 00 00
				00 00 00 00 00 FF FF FF
				FF FF FF FF FF FF FF FF
				FF FF FF FF FF FF FF FF
				FF FF FF FF FF FF FF FF
				FF FF FF FF FF FF FF FF
				FF FF FF FF FF FF FF FF
				FF FF FF FF FF FF FF FF
				FF FF FF FF FF FF FF FF
				FF FF FF FF FF 00 00 BA
				00 80 04 1B 00 00 FF 2C
				01 FF FF CC 03 E8 03 00
				C0 80 04 10 0A 18 00 79
				08 08 00 01 2C 01 06 00
				06 06 07 07 00 2C 01 01
				04 03 36 00 19 00 00 00
				02 00 01 28 04 35 00 19
				00 01 00 02 00 01 29 04
				34 00 18 00 02 00 02 00
				01 2A 83 33 00 17 00 03
				00 02 00 01 2B 03 32 00
				17 00 04 00 02 00 01 2C
				83 31 00 17 00 05 00 02
				00 01 2D 83 30 00 16 00
				06 00 05 00 02 26 83 2F
				00 16 00 07 00 05 00 02
				27 05 05 05 05 05 05 05
				05 05 05 05 05 05 05 05
				05 05 00 00 00 00 00 00
				00 00 00 00 00 00 00 00
				00 00 00 1B 00 06 00 A6
				00 14 64 00 01 1B 02 06
				32 32 50 00 50 00 50 50
				1E 03 0C 0C 14 28 04 00
				00 00 00 00 00 00 00 00
				00 18 00 80 07 01 07 07
				1D 1D 00 00 07 07 01 07
				07 1D 1D 00 00 07 04 04
				50 00 07 03 00 36 22 00
				05 0B 00 22 02 00 00 04
				0C 00 00 00 0C 00 00 00
				01 28 0C 11 11 00 0C 66
				66 AA 00 00 00 FF FF FF
				FF FF FF FF FF 51 51 51
				51 CD 0D 04 83 10 10 10
				10 61 24 64 01 1C 19 1E
				1F 17 16 1A 18 15 14 13
				11 12 04 05 03 06 FF FF
				FF FF FF FF FF FF FF FF
				FF FF FF FF FF FF FF 30
				2E 2F 28 27 2D 29 2A 2C
				2B 26 23 24 25 22 39 35
				36 3A 3B 3E 3F 31 3C 38
				3D 37 00 32 01 FF FF FF
				FF 00 10 00 10 00 10 00
				10 80 80 80 80 80 80 80
				80 80 80 80 80 80 80 80
				80 80 80 80 80 80 80 80
				80 80 80 80 80 80 80 80
				80 80 80 80 80 80 80 80
				80 80 80 80 80 80 80 80
				80 80 80 80 80 80 80 80
				80 80 80 80 80 80 80 80
				80 80 80 80 80 00 10 00
				10 00 10 00 10 00 00 1D
				FF FF FF FF FF FF FF 00
				00 0F 00 44 44
			];
		};

		config_3 { /* YFO R2 + Sharp */
			pr_number     = <2093014>;
			uncover_setting = [12 5A 19 05 0F];
			cover_setting = [0C 17 0C 25 0A];
			glove_setting = [0C 17 0C 25 0A];
			sensor_id = <0x2>;
			config = [
				50 4D 45 00 59 46 4F 00
				07 00 00 00 00 00 00 00
				00 00 00 00 00 00 00 00
				00 00 00 00 00 00 00 00
				00 4F 03 14 05 51 0E 70
				08 00 0F 7D 3D 79 3D 00
				00 00 00 11 1E 1E 05 6B
				08 60 01 2D 17 02 14 02
				F0 D2 F0 D2 6D 0D 05 46
				00 00 0F 12 8C 0F 0A 78
				00 01 01 07 04 04 32 28
				08 C8 26 26 80 80 00 00
				FF C0 53 5B 80 5A 19 01
				40 40 32 50 00 00 00 00
				4C 04 6C 07 3C 32 00 00
				00 00 4C 04 6C 07 1E 05
				1E 04 0A 04 0A 00 0A 04
				04 00 0A 78 02 00 7D 00
				02 00 C8 00 00 00 96 00
				00 00 00 01 05 0A 00 00
				00 78 00 96 00 32 00 00
				00 00 00 00 00 00 00 0D
				00 00 14 03 0C 0F 0A 00
				4B 00 00 FF FF FF FF FF
				FF FF FF FF FF FF FF FF
				FF FF FF FF FF FF FF FF
				FF FF FF FF FF FF FF FF
				FF FF FF FF 00 01 00 00
				32 00 14 00 14 00 64 00
				64 00 10 00 10 00 7D 00
				7D 00 40 66 58 1B 28 00
				FF FF FF FF FF FF FF FF
				FF FF FF FF FF FF FF FF
				01 00 00 00 00 00 00 00
				00 00 00 00 00 00 00 00
				00 00 00 00 00 00 00 FF
				00 FF 14 55 09 0E 3C 0A
				0F 64 64 00 00 00 00 00
				00 00 00 00 00 00 00 00
				00 00 00 00 00 FF FF FF
				FF FF FF FF FF FF FF FF
				FF FF FF FF FF FF FF FF
				FF FF FF FF FF FF FF FF
				FF FF FF FF FF FF FF FF
				FF FF FF FF FF FF FF FF
				FF FF FF FF FF FF FF FF
				FF FF FF FF FF FF FF FF
				FF FF FF FF FF 00 00 B7
				00 80 04 1B 00 00 FF 2C
				01 FF FF CC 03 E8 03 00
				C0 80 04 10 0A 18 00 79
				08 08 00 01 2C 01 06 00
				03 03 07 07 03 2C 01 01
				04 83 36 00 19 00 00 00
				02 00 01 28 04 35 00 19
				00 01 00 02 00 01 29 04
				34 00 18 00 02 00 02 00
				01 2A 03 33 00 17 00 03
				00 02 00 01 2B 03 32 00
				17 00 04 00 02 00 01 2C
				83 31 00 17 00 05 00 02
				00 01 2D 83 30 00 16 00
				06 00 05 00 02 26 83 2F
				00 16 00 07 00 05 00 02
				27 06 06 06 06 06 06 06
				06 06 06 06 05 05 05 05
				06 05 00 00 00 00 00 00
				00 00 00 00 00 00 00 00
				00 00 00 1B 00 06 00 A6
				00 14 64 00 01 1B 02 06
				32 32 50 00 50 00 50 50
				1E 03 0C 0C 14 28 04 00
				00 00 00 00 00 00 00 00
				00 18 00 80 07 01 07 07
				1D 1D 00 00 07 07 01 07
				07 1D 1D 00 00 07 04 04
				50 00 07 03 00 36 22 00
				05 0B 00 22 02 00 00 04
				0C 00 00 00 0C 00 00 00
				01 3C 0C 11 11 00 0C 66
				66 AA 00 00 00 FF FF FF
				FF FF FF FF FF 51 51 51
				51 CD 0D 04 83 10 10 10
				10 61 24 64 01 1C 19 1E
				1F 17 16 1A 18 15 14 13
				11 12 04 05 03 06 FF FF
				FF FF FF FF FF FF FF FF
				FF FF FF FF FF FF FF 30
				2E 2F 28 27 2D 29 2A 2C
				2B 26 23 24 25 22 39 35
				3C 3A 3B 3E 3F 31 36 38
				3D 37 00 32 01 FF FF FF
				FF 00 10 00 10 00 10 00
				10 80 80 80 80 80 80 80
				80 80 80 80 80 80 80 80
				80 80 80 80 80 80 80 80
				80 80 80 80 80 80 80 80
				80 80 80 80 80 80 80 80
				80 80 80 80 80 80 80 80
				80 80 80 80 80 80 80 80
				80 80 80 80 80 80 80 80
				80 80 80 80 80 00 10 00
				10 00 10 00 10 00 00 1D
				FF FF FF FF FF FF FF 00
				00 0F 00 44 44
			];
		};

		config_2 { /* LGIT */
			pr_number     = <2051324>;
			sensor_id = <0x1>;
			config = [
				50 4D 45 00 4C 47 00 02
				00 00 00 00 00 00 00 00
				00 00 00 00 00 00 00 00
				00 00 00 00 00 00 00 00
				00 4F 03 1E 05 51 0E 70
				08 00 0F 7D 3D 79 3D 00
				00 00 00 11 1E 1E 05 C2
				04 F8 00 2D 19 01 15 02
				F0 D2 F0 D2 25 0D 05 8C
				00 00 0F 12 80 0F 0A 78
				00 01 01 07 04 04 0A C0
				19 64 26 26 80 80 00 00
				C8 C0 53 5B 80 52 19 01
				40 40 32 50 00 00 00 00
				4C 04 6C 07 3C 32 00 00
				00 00 4C 04 6C 07 1E 05
				1E 04 0A 04 0A 00 0A 04
				04 00 0A 78 02 00 7D 00
				02 00 C8 00 00 00 96 00
				00 00 00 01 05 0A 00 00
				00 78 00 96 00 32 00 00
				00 00 00 00 00 00 00 0D
				00 00 14 03 0C 0F 0A 00
				4B 00 00 FF FF FF FF FF
				FF FF FF FF FF FF FF FF
				FF FF FF FF FF FF FF FF
				FF FF FF FF FF FF FF FF
				FF FF FF FF 00 01 00 00
				32 00 14 00 14 00 64 00
				64 00 10 00 10 00 7D 00
				7D 00 40 66 58 1B 28 00
				FF FF FF FF FF FF FF FF
				FF FF FF FF FF FF FF FF
				01 00 00 00 00 00 00 00
				00 00 00 00 00 00 00 00
				00 00 00 00 00 00 00 FF
				00 FF 14 55 09 0E 3C 0A
				0F 64 64 00 00 00 00 00
				00 00 00 00 00 00 00 00
				00 00 00 00 00 FF FF FF
				FF FF FF FF FF FF FF FF
				FF FF FF FF FF FF FF FF
				FF FF FF FF FF FF FF FF
				FF FF FF FF FF FF FF FF
				FF FF FF FF FF FF FF FF
				FF FF FF FF FF FF FF FF
				FF FF FF FF FF FF FF FF
				FF FF FF FF FF 00 00 BA
				00 80 04 1B 00 00 FF 2C
				01 FF FF CC 03 E8 03 00
				C0 80 04 10 0A 18 00 79
				08 08 00 01 2C 01 06 00
				06 06 07 07 00 2C 01 01
				04 83 36 00 19 00 00 00
				02 00 01 28 84 35 00 19
				00 01 00 02 00 01 29 84
				34 00 18 00 02 00 02 00
				01 2A 83 33 00 17 00 03
				00 02 00 01 2B 83 32 00
				17 00 04 00 02 00 01 2C
				83 31 00 17 00 05 00 02
				00 01 2D 83 30 00 16 00
				06 00 05 00 02 26 03 2F
				00 16 00 07 00 05 00 02
				27 05 05 05 05 05 05 05
				05 05 05 05 05 05 05 05
				05 05 00 00 00 00 00 00
				00 00 00 00 00 00 00 00
				00 00 00 1B 00 06 00 A6
				00 14 64 00 01 1B 02 00
				08 32 A0 00 A0 00 50 50
				1E 03 0C 0C 14 28 04 00
				00 00 00 00 00 00 00 00
				00 18 00 80 07 01 07 07
				1D 1D 00 00 07 07 01 07
				07 1D 1D 00 00 07 04 04
				50 00 07 03 00 36 22 00
				05 0B 00 22 02 00 00 04
				0C 00 00 00 0C 00 00 00
				01 28 0C 11 11 00 0C 66
				66 AA 00 00 00 FF FF FF
				FF FF FF FF FF 51 51 51
				51 CD 0D 04 83 10 10 10
				10 61 24 64 01 1C 19 1E
				1F 17 16 1A 18 15 14 13
				11 12 04 05 03 06 FF FF
				FF FF FF FF FF FF FF FF
				FF FF FF FF FF FF FF 30
				2E 2F 28 27 2D 29 2A 2C
				2B 26 23 24 25 22 39 35
				36 3A 3B 3E 3F 31 3C 38
				3D 37 00 32 01 FF FF FF
				FF 00 10 00 10 00 10 00
				10 80 80 80 80 80 80 80
				80 80 80 80 80 80 80 80
				80 80 80 80 80 80 80 80
				80 80 80 80 80 80 80 80
				80 80 80 80 80 80 80 80
				80 80 80 80 80 80 80 80
				80 80 80 80 80 80 80 80
				80 80 80 80 80 80 80 80
				80 80 80 80 80 00 10 00
				10 00 10 00 10 00 00 1D
				FF FF FF FF FF FF FF 00
				00 0F 00 00 00
			];
		};

		config_1 { /* YFO R2 */
			pr_number     = <2051324>;
			sensor_id = <0x2>;
			config = [
				50 4D 45 00 59 46 4F 00
				04 00 00 00 00 00 00 00
				00 00 00 00 00 00 00 00
				00 00 00 00 00 00 00 00
				00 4F 03 1E 05 51 0E 70
				08 00 0F 7D 3D 79 3D 00
				00 00 00 11 1E 1E 05 6B
				08 60 01 2D 17 02 14 02
				F0 D2 F0 D2 25 0D 05 8C
				00 00 0F 12 80 0F 0A 78
				00 01 01 07 04 04 0A C0
				19 64 26 26 80 80 00 00
				C8 C0 53 5B 80 5A 19 01
				40 40 32 50 00 00 00 00
				4C 04 6C 07 3C 32 00 00
				00 00 4C 04 6C 07 1E 05
				1E 04 0A 04 0A 00 0A 04
				04 00 0A 78 02 00 7D 00
				02 00 C8 00 00 00 96 00
				00 00 00 01 05 0A 00 00
				00 78 00 96 00 32 00 00
				00 00 00 00 00 00 00 0D
				00 00 14 03 0C 0F 0A 00
				4B 00 00 FF FF FF FF FF
				FF FF FF FF FF FF FF FF
				FF FF FF FF FF FF FF FF
				FF FF FF FF FF FF FF FF
				FF FF FF FF 00 01 00 00
				32 00 14 00 14 00 64 00
				64 00 10 00 10 00 7D 00
				7D 00 40 66 58 1B 28 00
				FF FF FF FF FF FF FF FF
				FF FF FF FF FF FF FF FF
				01 00 00 00 00 00 00 00
				00 00 00 00 00 00 00 00
				00 00 00 00 00 00 00 FF
				00 FF 14 55 09 0E 3C 0A
				0F 64 64 00 00 00 00 00
				00 00 00 00 00 00 00 00
				00 00 00 00 00 FF FF FF
				FF FF FF FF FF FF FF FF
				FF FF FF FF FF FF FF FF
				FF FF FF FF FF FF FF FF
				FF FF FF FF FF FF FF FF
				FF FF FF FF FF FF FF FF
				FF FF FF FF FF FF FF FF
				FF FF FF FF FF FF FF FF
				FF FF FF FF FF 00 00 B7
				00 80 04 1B 00 00 FF 2C
				01 FF FF CC 03 E8 03 00
				C0 80 04 10 0A 18 00 79
				08 08 00 01 2C 01 06 00
				03 03 07 07 03 2C 01 01
				04 03 36 00 19 00 00 00
				02 00 01 28 04 35 00 19
				00 01 00 02 00 01 29 84
				34 00 18 00 02 00 02 00
				01 2A 83 33 00 17 00 03
				00 02 00 01 2B 83 32 00
				17 00 04 00 02 00 01 2C
				83 31 00 17 00 05 00 02
				00 01 2D 03 30 00 16 00
				06 00 05 00 02 26 03 2F
				00 16 00 07 00 05 00 02
				27 06 06 06 06 06 06 06
				06 06 06 06 05 05 05 05
				06 05 00 00 00 00 00 00
				00 00 00 00 00 00 00 00
				00 00 00 1B 00 06 00 A6
				00 14 64 00 01 1B 02 00
				08 32 A0 00 A0 00 50 50
				1E 03 0C 0C 14 28 04 00
				00 00 00 00 00 00 00 00
				00 18 00 80 07 01 07 07
				1D 1D 00 00 07 07 01 07
				07 1D 1D 00 00 07 04 04
				50 00 07 03 00 36 22 00
				05 0B 00 22 02 00 00 04
				0C 00 00 00 0C 00 00 00
				01 3C 0C 11 11 00 0C 66
				66 00 00 00 00 FF FF FF
				FF FF FF FF FF 51 51 51
				51 CD 0D 04 83 10 10 10
				10 61 24 64 01 1C 19 1E
				1F 17 16 1A 18 15 14 13
				11 12 04 05 03 06 FF FF
				FF FF FF FF FF FF FF FF
				FF FF FF FF FF FF FF 30
				2E 2F 28 27 2D 29 2A 2C
				2B 26 23 24 25 22 39 35
				3C 3A 3B 3E 3F 31 36 38
				3D 37 00 32 01 FF FF FF
				FF 00 10 00 10 00 10 00
				10 80 80 80 80 80 80 80
				80 80 80 80 80 80 80 80
				80 80 80 80 80 80 80 80
				80 80 80 80 80 80 80 80
				80 80 80 80 80 80 80 80
				80 80 80 80 80 80 80 80
				80 80 80 80 80 80 80 80
				80 80 80 80 80 80 80 80
				80 80 80 80 80 00 10 00
				10 00 10 00 10 00 00 1D
				FF FF FF FF FF FF FF 00
				00 0F 00 00 00
			];
		};

		config_0 { /* YFO R1 */
			pr_number     = <2051324>;
			uncover_setting = [0F 5B 19 15 0C];
			cover_setting = [0C 17 0C 25 0A];
			glove_setting = [0C 17 0C 25 0A];
			sensor_id = <0x0>;
			config = [
				4F 32 00 06 00 00 00 00
				00 00 00 00 00 00 00 00
				00 00 00 00 00 00 00 00
				00 00 00 00 00 00 00 00
				00 7F 03 1E 05 51 0E 70
				08 00 0F 00 40 00 40 00
				00 00 00 11 1E 1E 05 59
				08 E3 01 2D 16 01 17 01
				F0 D2 F0 D2 25 0D 05 8C
				00 00 0C 0F 80 0F 0A 78
				00 01 01 07 04 04 0A C0
				19 64 26 26 80 80 00 00
				C8 C0 53 5B 80 5B 19 01
				40 40 32 50 00 00 00 00
				4C 04 6C 07 3C 32 00 00
				00 00 4C 04 6C 07 1E 05
				1E 04 0A 04 0A 00 0A 04
				04 00 0A 78 02 00 7D 00
				02 00 C8 00 00 00 96 00
				00 00 00 01 15 0A 00 00
				00 78 00 96 00 32 00 00
				00 00 00 00 00 00 00 0D
				00 00 14 03 0C 0F 0A 00
				4B 00 00 FF FF FF FF FF
				FF FF FF FF FF FF FF FF
				FF FF FF FF FF FF FF FF
				FF FF FF FF FF FF FF FF
				FF FF FF FF 00 01 00 00
				32 00 14 00 14 00 64 00
				64 00 10 00 10 00 7D 00
				7D 00 40 66 58 1B 28 00
				FF FF FF FF FF FF FF FF
				FF FF FF FF FF FF FF FF
				01 00 00 00 00 00 00 00
				00 00 00 00 00 00 00 00
				00 00 00 00 00 00 00 FF
				00 FF 14 55 09 0E 3C 0A
				0F 64 64 00 00 00 00 00
				00 00 00 00 00 00 00 00
				00 00 00 00 00 FF FF FF
				FF FF FF FF FF FF FF FF
				FF FF FF FF FF FF FF FF
				FF FF FF FF FF FF FF FF
				FF FF FF FF FF FF FF FF
				FF FF FF FF FF FF FF FF
				FF FF FF FF FF FF FF FF
				FF FF FF FF FF FF FF FF
				FF FF FF FF FF 00 00 C8
				00 80 04 1B 00 00 FF 2C
				01 FF FF CC 03 E8 03 00
				C0 80 04 10 0A 18 00 79
				08 08 00 01 2C 01 06 00
				03 03 07 07 03 2C 01 01
				04 03 29 00 12 00 00 00
				03 00 01 25 03 28 00 12
				00 02 00 03 00 01 27 82
				26 00 11 00 04 00 03 00
				01 28 82 25 00 11 00 06
				00 07 00 02 24 02 24 00
				10 00 08 00 07 00 02 25
				82 23 00 10 00 0A 00 07
				00 02 26 02 22 00 0F 00
				0B 00 07 00 02 27 02 21
				00 0F 00 11 00 04 00 01
				25 04 05 04 05 05 04 04
				04 04 04 05 04 04 04 04
				04 04 00 00 00 00 00 00
				00 00 00 00 00 00 00 00
				00 00 00 2B 00 06 00 A6
				00 14 64 00 01 1B 02 06
				32 32 50 00 50 00 50 50
				1E 03 0C 0C 14 28 04 00
				00 00 00 00 00 00 00 00
				00 11 00 00 07 01 07 07
				1D 1D 00 00 07 07 01 07
				07 1D 1D 00 00 07 04 04
				50 00 07 03 00 29 22 00
				05 0B 00 22 02 00 00 00
				0C 00 00 00 0C 00 00 00
				01 23 0C 00 00 00 0C 00
				00 AA 00 00 00 FF FF FF
				FF FF FF FF FF 51 51 51
				51 CD 0D 04 83 10 10 10
				10 61 24 64 01 1C 19 1E
				1F 17 16 1A 18 15 10 11
				0B 0F 13 0E 12 0D FF FF
				FF FF FF FF FF FF FF FF
				FF FF FF FF FF FF FF 30
				2E 2F 28 27 2D 29 2A 2C
				2B 26 23 24 25 22 39 35
				36 3A 3B 3C 3F 31 3E 38
				3D 37 00 32 01 FF FF FF
				FF 00 10 00 10 00 10 00
				10 80 80 80 80 80 80 80
				80 80 80 80 80 80 80 80
				80 80 80 80 80 80 80 80
				80 80 80 80 80 80 80 80
				80 80 80 80 80 80 80 80
				80 80 80 80 80 80 80 80
				80 80 80 80 80 80 80 80
				80 80 80 80 80 80 80 80
				80 80 80 80 80 00 10 00
				10 00 10 00 10 00 00 FF
				FF FF FF 1D FF FF FF 00
				00 0F 00 00 00
			];
		};
	};
};
